VERSION "created by canmatrix"

NS_ :

BS_:

BU_: ABS BCU ESL PKE VIU BMS DTU OBC

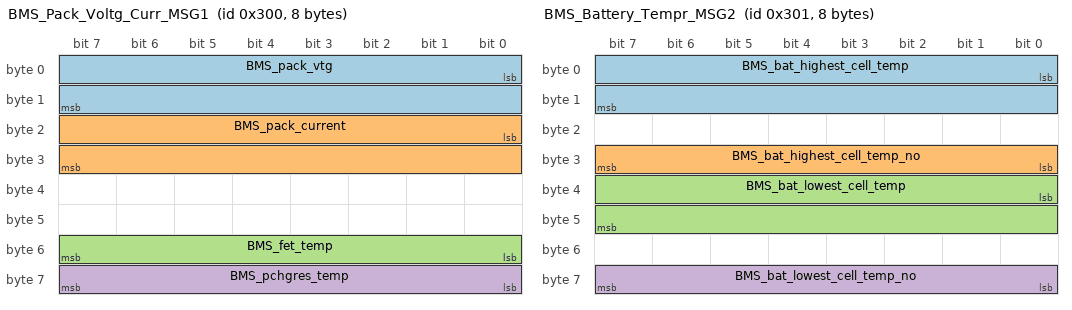
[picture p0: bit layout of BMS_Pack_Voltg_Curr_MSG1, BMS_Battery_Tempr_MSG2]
BO_ 768 BMS_Pack_Voltg_Curr_MSG1: 8 BMS
 SG_ BMS_pack_vtg : 0|16@1+ (0.01,0) [0|65535] "V"  DTU,OBC,VIU
 SG_ BMS_pack_current : 16|16@1- (0.01,0) [-32768|32767] "A"  DTU,OBC,VIU
 SG_ BMS_fet_temp : 48|8@1- (1,0) [-128|127] "degC"  DTU,OBC,VIU
 SG_ BMS_pchgres_temp : 56|8@1- (1,0) [-128|127] "degC"  DTU,OBC,VIU

BO_ 769 BMS_Battery_Tempr_MSG2: 8 BMS
 SG_ BMS_bat_highest_cell_temp : 0|16@1- (0.01,0) [-32768|32767] "degC"  DTU,VIU
 SG_ BMS_bat_highest_cell_temp_no : 24|8@1+ (1,0) [0|255] ""  DTU,VIU
 SG_ BMS_bat_lowest_cell_temp : 32|16@1- (0.01,0) [-32768|32767] "degC"  DTU,VIU
 SG_ BMS_bat_lowest_cell_temp_no : 56|8@1+ (1,0) [0|255] ""  DTU,VIU

BO_ 770 BMS_Battery_CS_Tempr_MSG3: 8 BMS
 SG_ BMS_delta_cell_temp : 0|16@1- (0.01,0) [-32768|32767] "degC"  DTU,VIU
 SG_ BMS_cstemp : 16|16@1- (0.01,0) [-32768|32767] "degC"  DTU,VIU
 SG_ BMS_delta_cell_vtg : 32|16@1- (0.001,0) [-32768|32767] "V"  DTU,VIU

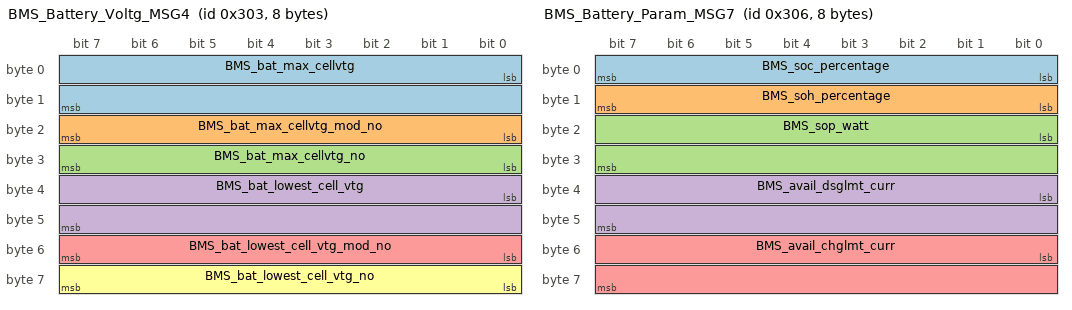
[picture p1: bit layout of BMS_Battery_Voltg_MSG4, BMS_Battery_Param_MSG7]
BO_ 771 BMS_Battery_Voltg_MSG4: 8 BMS
 SG_ BMS_bat_max_cellvtg : 0|16@1+ (0.001,0) [0|65535] "V"  DTU,OBC,VIU
 SG_ BMS_bat_max_cellvtg_mod_no : 16|8@1+ (1,0) [0|255] ""  DTU,OBC,VIU
 SG_ BMS_bat_max_cellvtg_no : 24|8@1+ (1,0) [0|255] ""  DTU,OBC,VIU
 SG_ BMS_bat_lowest_cell_vtg : 32|16@1+ (0.001,0) [0|65535] "V"  DTU,OBC,VIU
 SG_ BMS_bat_lowest_cell_vtg_mod_no : 48|8@1+ (1,0) [0|255] ""  DTU,OBC,VIU
 SG_ BMS_bat_lowest_cell_vtg_no : 56|8@1+ (1,0) [0|255] ""  DTU,OBC,VIU

BO_ 772 BMS_Battery_Param_MSG5: 8 BMS
 SG_ BMS_bat_full_capacity : 0|16@1+ (0.01,0) [0|65535] "Ah"  DTU,OBC,VIU
 SG_ BMS_bat_remaining_capacity : 32|16@1+ (0.001,0) [0|65535] "Ah"  DTU,OBC,VIU
 SG_ BMS_bat_no_of_cycle : 48|16@1+ (1,0) [0|65535] ""  DTU,OBC,VIU

BO_ 773 BMS_Battery_State_MSG6: 8 BMS
 SG_ BMS_state : 0|6@1+ (1,0) [0|63] "State"  BCU,DTU,OBC,VIU
 SG_ BMS_scd_fb_status : 6|1@1+ (1,0) [0|1] "Status"  BCU,DTU,OBC,VIU
 SG_ BMS_charger_detect_status : 7|1@1+ (1,0) [0|1] "Status"  BCU,DTU,OBC,VIU
 SG_ BMS_fet_state : 8|3@1+ (1,0) [0|7] "State"  BCU,DTU,OBC,VIU
 SG_ BMS_CS_state : 11|2@1+ (1,0) [0|3] "State"  BCU,DTU,OBC,VIU
 SG_ BMS_chg_mcu_status : 13|1@1+ (1,0) [0|1] "Status"  BCU,DTU,OBC,VIU
 SG_ BMS_dchg_mcu_status : 14|1@1+ (1,0) [0|1] "Status"  BCU,DTU,OBC,VIU
 SG_ BMS_dchg_fb_status : 15|1@1+ (1,0) [0|1] "Status"  BCU,DTU,OBC,VIU
 SG_ BMS_calib_start_status : 16|1@1+ (1,0) [0|1] "Status"  BCU,DTU,OBC,VIU
 SG_ BMS_sop_derating_flag : 17|1@1+ (1,0) [0|1] "Status"  BCU,DTU,OBC,VIU
 SG_ BMS_charger_plugged_status : 18|1@1+ (1,0) [0|1] "Status"  BCU,DTU,OBC,VIU
 SG_ BMS_cstemp_warn_status : 19|1@1+ (1,0) [0|1] "Status"  BCU,DTU,OBC,VIU
 SG_ BMS_regen_disable_flag : 20|1@1+ (1,0) [0|1] "Status"  BCU,DTU,OBC,VIU
 SG_ BMS_diagchk_BattStatus : 24|2@1+ (1,0) [0|3] "Status"  BCU,DTU,OBC,VIU
 SG_ BMS_diagchk_BattTemp : 26|2@1+ (1,0) [0|3] "Status"  BCU,DTU,OBC,VIU
 SG_ BMS_diagchk_BattVtg : 28|2@1+ (1,0) [0|3] "Status"  BCU,DTU,OBC,VIU
 SG_ BMS_diagchk_CoolantTemp : 30|2@1+ (1,0) [0|3] "Status"  BCU,DTU,OBC,VIU
 SG_ BMS_cantx_status : 32|1@1+ (1,0) [0|1] "Status"  BCU,DTU,OBC,VIU
 SG_ BMS_bcucanrx_status : 33|1@1+ (1,0) [0|1] "Status"  BCU,DTU,OBC,VIU
 SG_ BMS_dtucanrx_status : 34|1@1+ (1,0) [0|1] "Status"  BCU,DTU,OBC,VIU
 SG_ BMS_obccanrx_status : 35|1@1+ (1,0) [0|1] "Status"  BCU,DTU,OBC,VIU
 SG_ BMS_viucanrx_status : 36|1@1+ (1,0) [0|1] "Status"  BCU,DTU,OBC,VIU
 SG_ BMS_abscanrx_status : 37|1@1+ (1,0) [0|1] "Status"  BCU,DTU,OBC,VIU
 SG_ BMS_pkecanrx_status : 38|1@1+ (1,0) [0|1] "Status"  BCU,DTU,OBC,VIU
 SG_ BMS_esclcanrx_status : 39|1@1+ (1,0) [0|1] "Status"  BCU,DTU,OBC,VIU
 SG_ BMS_can_state : 40|2@1+ (1,0) [0|3] "x"  BCU,DTU,OBC,VIU
 SG_ BMS_chgr_full_status : 42|1@1+ (1,0) [0|1] "Status"  BCU,DTU,OBC,VIU
 SG_ BMS_fchgr_pres_status : 43|1@1+ (1,0) [0|1] "Status"  BCU,DTU,OBC,VIU
 SG_ BMS_chgr_fault_status : 44|1@1+ (1,0) [0|1] "Status"  BCU,DTU,OBC,VIU
 SG_ BMS_eol_mode : 45|1@1+ (1,0) [0|1] "Status"  BCU,DTU,OBC,VIU

BO_ 774 BMS_Battery_Param_MSG7: 8 BMS
 SG_ BMS_soc_percentage : 0|8@1+ (1,0) [0|255] "%"  DTU,OBC,VIU
 SG_ BMS_soh_percentage : 8|8@1+ (1,0) [0|255] "%"  DTU,OBC,VIU
 SG_ BMS_sop_watt : 16|16@1+ (1,0) [0|65535] "W"  DTU,OBC,VIU
 SG_ BMS_avail_dsglmt_curr : 32|16@1+ (0.01,0) [0|65535] "A"  DTU,OBC,VIU
 SG_ BMS_avail_chglmt_curr : 48|16@1+ (0.01,0) [0|65535] "A"  DTU,OBC,VIU

BO_ 512 BMS_AFE_MCU_Faults_MSG9: 8 BMS
 SG_ BMS_afe_cov_fault : 0|1@1+ (1,0) [0|1] "Status"  BCU,DTU,OBC,VIU
 SG_ BMS_afe_cuv_fault : 1|1@1+ (1,0) [0|1] "Status"  BCU,DTU,OBC,VIU
 SG_ BMS_afe_cot_chg_fault : 2|1@1+ (1,0) [0|1] "Status"  BCU,DTU,OBC,VIU
 SG_ BMS_afe_cot_dchg_fault : 3|1@1+ (1,0) [0|1] "Status"  BCU,DTU,OBC,VIU
 SG_ BMS_afe_cut_chg_fault : 4|1@1+ (1,0) [0|1] "Status"  BCU,DTU,OBC,VIU
 SG_ BMS_afe_cut_dchg_fault : 5|1@1+ (1,0) [0|1] "Status"  BCU,DTU,OBC,VIU
 SG_ BMS_afe_oc_chg_fault : 6|1@1+ (1,0) [0|1] "Status"  BCU,DTU,OBC,VIU
 SG_ BMS_afe_oc_dchg_fault : 7|1@1+ (1,0) [0|1] "Status"  BCU,DTU,OBC,VIU
 SG_ BMS_afe_sc_detetction_fault : 8|1@1+ (1,0) [0|1] "Status"  BCU,DTU,OBC,VIU
 SG_ BMS_afe_overload_detect_fault : 9|1@1+ (1,0) [0|1] "Status"  BCU,DTU,OBC,VIU
 SG_ BMS_afe_fet_off_fault : 10|1@1+ (1,0) [0|1] "Status"  BCU,DTU,OBC,VIU
 SG_ BMS_afe_oc_fault : 11|1@1+ (1,0) [0|1] "Status"  BCU,DTU,OBC,VIU
 SG_ BMS_afe_otf_fault : 12|1@1+ (1,0) [0|1] "Status"  BCU,DTU,OBC,VIU
 SG_ BMS_chgfetoff_fault : 13|1@1+ (1,0) [0|1] "Status"  BCU,DTU,OBC,VIU
 SG_ BMS_dsgfetoff_fault : 14|1@1+ (1,0) [0|1] ""  BCU,DTU,OBC,VIU
 SG_ BMS_cov_fault : 16|1@1+ (1,0) [0|1] "Status"  BCU,DTU,OBC,VIU
 SG_ BMS_cuv_fault : 17|1@1+ (1,0) [0|1] "Status"  BCU,DTU,OBC,VIU
 SG_ BMS_ddsg_fault : 18|1@1+ (1,0) [0|1] "Status"  BCU,DTU,OBC,VIU
 SG_ BMS_del_cv_fault : 19|1@1+ (1,0) [0|1] "Status"  BCU,DTU,OBC,VIU
 SG_ BMS_pchg_tout_fault : 20|1@1+ (1,0) [0|1] "Status"  BCU,DTU,OBC,VIU
 SG_ BMS_del_ct_fault : 21|1@1+ (1,0) [0|1] "Status"  BCU,DTU,OBC,VIU
 SG_ BMS_hostl_i2c_fault : 22|1@1+ (1,0) [0|1] "Status"  BCU,DTU,OBC,VIU
 SG_ BMS_hostu_i2c_fault : 23|1@1+ (1,0) [0|1] "Status"  BCU,DTU,OBC,VIU
 SG_ BMS_cot_chg_fault : 24|1@1+ (1,0) [0|1] "Status"  BCU,DTU,OBC,VIU
 SG_ BMS_cot_dsg_fault : 25|1@1+ (1,0) [0|1] "Status"  BCU,DTU,OBC,VIU
 SG_ BMS_cut_chg_fault : 26|1@1+ (1,0) [0|1] "Status"  BCU,DTU,OBC,VIU
 SG_ BMS_cut_dsg_fault : 27|1@1+ (1,0) [0|1] "Status"  BCU,DTU,OBC,VIU
 SG_ BMS_fot_fault : 28|1@1+ (1,0) [0|1] "Status"  BCU,DTU,OBC,VIU
 SG_ BMS_csot_fault : 29|1@1+ (1,0) [0|1] "Status"  BCU,DTU,OBC,VIU
 SG_ BMS_afedieot_fault : 30|1@1+ (1,0) [0|1] "Status"  BCU,DTU,OBC,VIU
 SG_ BMS_imd_fault : 31|1@1+ (1,0) [0|1] "Status"  BCU,DTU,OBC,VIU
 SG_ BMS_cvow_fault : 33|1@1+ (1,0) [0|1] "Status"  BCU,DTU,OBC,VIU
 SG_ BMS_ctow_fault : 34|1@1+ (1,0) [0|1] "Status"  BCU,DTU,OBC,VIU
 SG_ BMS_nctow_fault : 35|1@1+ (1,0) [0|1] "Status"  BCU,DTU,OBC,VIU
 SG_ BMS_cs_ic_fail_fault : 36|1@1+ (1,0) [0|1] "Status"  BCU,DTU,OBC,VIU
 SG_ BMS_imd_ic_fail_fault : 37|1@1+ (1,0) [0|1] "Status"  BCU,DTU,OBC,VIU
 SG_ BMS_ftow_fault : 38|1@1+ (1,0) [0|1] "Status"  BCU,DTU,OBC,VIU
 SG_ BMS_cstow_fault : 39|1@1+ (1,0) [0|1] "Status"  BCU,DTU,OBC,VIU
 SG_ BMS_aps_scd_fault : 40|1@1+ (1,0) [0|1] "Status"  BCU,DTU,OBC,VIU
 SG_ BMS_aps_ot_fault : 41|1@1+ (1,0) [0|1] "Status"  BCU,DTU,OBC,VIU
 SG_ BMS_aps_ov_fault : 42|1@1+ (1,0) [0|1] "Status"  BCU,DTU,OBC,VIU
 SG_ BMS_aps_oc_fault : 43|1@1+ (1,0) [0|1] "Status"  BCU,DTU,OBC,VIU
 SG_ BMS_fetchg_short_fault : 44|1@1+ (1,0) [0|1] "Status"  BCU,DTU,OBC,VIU
 SG_ BMS_fetdsg_short_fault : 45|1@1+ (1,0) [0|1] "Status"  BCU,DTU,OBC,VIU
 SG_ BMS_pchg_pk_fault : 46|1@1+ (1,0) [0|1] "Status"  BCU,DTU,OBC,VIU
 SG_ BMS_crit_rel_fault : 47|1@1+ (1,0) [0|1] "Status"  BCU,DTU,OBC,VIU
 SG_ BMS_pchg_rot_fault : 48|1@1+ (1,0) [0|1] "Status"  BCU,DTU,OBC,VIU
 SG_ BMS_pchg_rtow_fault : 49|1@1+ (1,0) [0|1] "Status"  BCU,DTU,OBC,VIU
 SG_ BMS_chg_hb_fault : 50|1@1+ (1,0) [0|1] "Status"  BCU,DTU,OBC,VIU
 SG_ BMS_hvil_fault : 51|1@1+ (1,0) [0|1] "Status"  BCU,DTU,OBC,VIU
 SG_ BMS_dsgoff_rel_fault : 52|1@1+ (1,0) [0|1] "Status"  BCU,DTU,OBC,VIU
 SG_ BMS_hazard_fault : 53|1@1+ (1,0) [0|1] "Status"  BCU,DTU,OBC,VIU
 SG_ BMS_hw_scd_fault : 54|1@1+ (1,0) [0|1] "Status"  BCU,DTU,OBC,VIU
 SG_ BMS_sysfail_fault : 55|1@1+ (1,0) [0|1] "Status"  BCU,DTU,OBC,VIU
 SG_ BMS_other_i2c_fault : 56|1@1+ (1,0) [0|1] "Status"  BCU,DTU,OBC,VIU
 SG_ BMS_aps_oclat_fault : 57|1@1+ (1,0) [0|1] "Status"  BCU,DTU,OBC,VIU
 SG_ BMS_aps_oclat_permfault : 58|1@1+ (1,0) [0|1] "Status"  BCU,DTU,OBC,VIU
 SG_ BMS_ext_opdis_fault : 59|1@1+ (1,0) [0|1] "Status"  BCU,DTU,OBC,VIU
 SG_ BMS_false_chgr_fault : 60|1@1+ (1,0) [0|1] "Status"  BCU,DTU,OBC,VIU
 SG_ BMS_occ1_fault : 61|1@1+ (1,0) [0|1] "Status"  BCU,DTU,OBC,VIU
 SG_ BMS_occ2_fault : 62|1@1+ (1,0) [0|1] "Status"  BCU,DTU,OBC,VIU
 SG_ BMS_occ3_fault : 63|1@1+ (1,0) [0|1] "Status"  BCU,DTU,OBC,VIU

BO_ 513 BMS_Warning_MSG10: 8 BMS
 SG_ BMS_bat_cov_warning : 0|1@1+ (1,0) [0|1] "Status"  BCU,DTU,OBC,VIU
 SG_ BMS_bat_cuv_warning : 1|1@1+ (1,0) [0|1] "Status"  BCU,DTU,OBC,VIU
 SG_ BMS_bat_del_v_warning : 2|1@1+ (1,0) [0|1] "Status"  BCU,DTU,OBC,VIU
 SG_ BMS_bat_cot_warning : 3|1@1+ (1,0) [0|1] "Status"  BCU,DTU,OBC,VIU
 SG_ BMS_bat_cut_warning : 4|1@1+ (1,0) [0|1] "Status"  BCU,DTU,OBC,VIU
 SG_ BMS_bat_del_ct_warning : 5|1@1+ (1,0) [0|1] "Status"  BCU,DTU,OBC,VIU
 SG_ BMS_bat_fot_warning : 6|1@1+ (1,0) [0|1] "Status"  BCU,DTU,OBC,VIU
 SG_ BMS_bat_csot_warning : 7|1@1+ (1,0) [0|1] "Status"  BCU,DTU,OBC,VIU
 SG_ BMS_bat_afedieot_warning : 8|1@1+ (1,0) [0|1] "Status"  BCU,DTU,OBC,VIU
 SG_ BMS_bat_occ_warning : 9|1@1+ (1,0) [0|1] "Status"  BCU,DTU,OBC,VIU
 SG_ BMS_bat_ocd_warning : 10|1@1+ (1,0) [0|1] "Status"  BCU,DTU,OBC,VIU
 SG_ BMS_bat_pusoc_warning : 11|1@1+ (1,0) [0|1] "Status"  BCU,DTU,OBC,VIU
 SG_ BMS_hvil_warning : 12|1@1+ (1,0) [0|1] "Status"  BCU,DTU,OBC,VIU
 SG_ BMS_bat_imd_warning : 13|1@1+ (1,0) [0|1] "Status"  BCU,DTU,OBC,VIU
 SG_ BMS_batcrit_lvl1_warning : 14|1@1+ (1,0) [0|1] "Status"  BCU,DTU,OBC,VIU
 SG_ BMS_batcrit_lvl2_warning : 15|1@1+ (1,0) [0|1] "Status"  BCU,DTU,OBC,VIU
 SG_ BMS_hostl_i2c_warning : 16|1@1+ (1,0) [0|1] "Status"  BCU,DTU,OBC,VIU
 SG_ BMS_hostu_i2c_warning : 17|1@1+ (1,0) [0|1] "Status"  BCU,DTU,OBC,VIU
 SG_ BMS_pump_oload_warning : 18|1@1+ (1,0) [0|1] "Status"  BCU,DTU,OBC,VIU
 SG_ BMS_dpdsg_warning : 19|1@1+ (1,0) [0|1] "Status"  BCU,DTU,OBC,VIU
 SG_ BMS_cotc_warning : 20|1@1+ (1,0) [0|1] "Status"  BCU,DTU,OBC,VIU
 SG_ BMS_cutc_warning : 21|1@1+ (1,0) [0|1] "Status"  BCU,DTU,OBC,VIU

BO_ 514 BMS_Iso_Resist_MSG11: 8 BMS
 SG_ BMS_iso_res_pcgnd : 0|32@1- (0.001,0) [-2147483648|2147483647] "Ohm"  DTU,OBC,VIU
 SG_ BMS_iso_res_ncgnd : 32|32@1- (0.001,0) [-2147483648|2147483647] "Ohm"  DTU,OBC,VIU

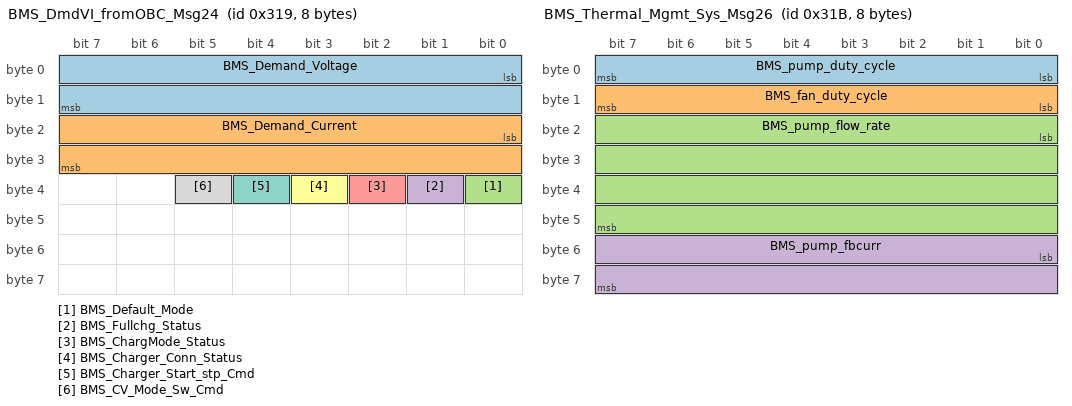
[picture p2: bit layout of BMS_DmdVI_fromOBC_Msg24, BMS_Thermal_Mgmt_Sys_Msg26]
BO_ 793 BMS_DmdVI_fromOBC_Msg24: 8 BMS
 SG_ BMS_Demand_Voltage : 0|16@1+ (0.1,0) [0|65535] "V"  OBC,VIU
 SG_ BMS_Demand_Current : 16|16@1- (0.01,0) [-32768|32767] "A"  OBC,VIU
 SG_ BMS_Default_Mode : 32|1@1+ (1,0) [0|1] ""  OBC,VIU
 SG_ BMS_Fullchg_Status : 33|1@1+ (1,0) [0|1] ""  OBC,VIU
 SG_ BMS_ChargMode_Status : 34|1@1+ (1,0) [0|1] "Status"  OBC,VIU
 SG_ BMS_Charger_Conn_Status : 35|1@1+ (1,0) [0|1] "Status"  OBC,VIU
 SG_ BMS_Charger_Start_stp_Cmd : 36|1@1+ (1,0) [0|1] "Cmd"  OBC,VIU
 SG_ BMS_CV_Mode_Sw_Cmd : 37|1@1+ (1,0) [0|1] "Mode"  OBC,VIU

BO_ 794 BMS_Heart_beat_Msg25: 8 BMS
 SG_ BMS_code_m25 : 0|8@1+ (1,0) [0|255] "ECUs"  BCU,DTU,OBC,VIU
 SG_ BMS_Rolling_Counter : 8|8@1+ (1,0) [0|255] ""  BCU,DTU,OBC,VIU

BO_ 795 BMS_Thermal_Mgmt_Sys_Msg26: 8 BMS
 SG_ BMS_pump_duty_cycle : 0|8@1+ (1,0) [0|255] "count"  BCU,DTU,OBC,VIU
 SG_ BMS_fan_duty_cycle : 8|8@1+ (1,0) [0|255] "%"  BCU,DTU,OBC,VIU
 SG_ BMS_pump_flow_rate : 16|32@1+ (1,0) [0|4294967295] "lpm"  BCU,DTU,OBC,VIU
 SG_ BMS_pump_fbcurr : 48|16@1- (0.001,0) [-32768|32767] "A"  BCU,DTU,OBC,VIU

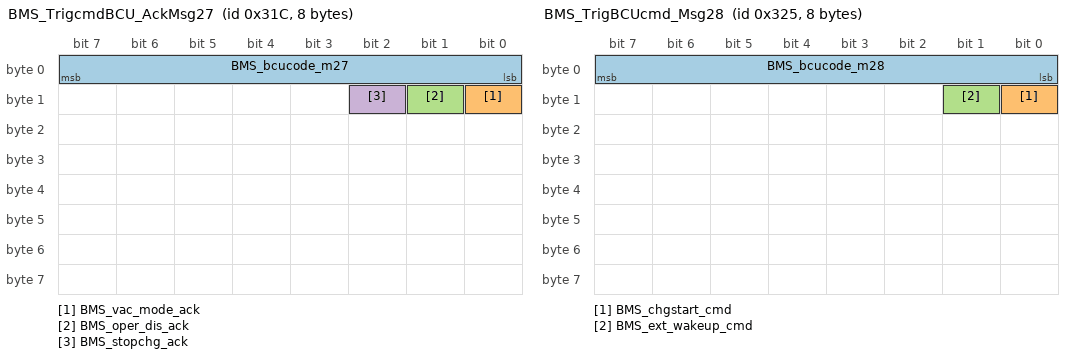
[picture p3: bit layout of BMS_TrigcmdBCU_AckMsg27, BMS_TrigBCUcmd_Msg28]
BO_ 796 BMS_TrigcmdBCU_AckMsg27: 8 BMS
 SG_ BMS_bcucode_m27 : 0|8@1+ (1,0) [0|255] ""  BCU,DTU,OBC,VIU
 SG_ BMS_vac_mode_ack : 8|1@1+ (1,0) [0|1] ""  BCU,DTU,OBC,VIU
 SG_ BMS_oper_dis_ack : 9|1@1+ (1,0) [0|1] ""  BCU,DTU,OBC,VIU
 SG_ BMS_stopchg_ack : 10|1@1+ (1,0) [0|1] ""  BCU,DTU,OBC,VIU

BO_ 805 BMS_TrigBCUcmd_Msg28: 8 BMS
 SG_ BMS_bcucode_m28 : 0|8@1+ (1,0) [0|255] ""  BCU,DTU,OBC,VIU
 SG_ BMS_chgstart_cmd : 8|1@1+ (1,0) [0|1] ""  BCU,DTU,OBC,VIU
 SG_ BMS_ext_wakeup_cmd : 9|1@1+ (1,0) [0|1] ""  BCU,DTU,OBC,VIU

BO_ 2028 BMS_Phy_RespMsg29: 8 BMS
 SG_ BMS_uds_frame : 0|64@1+ (1,0) [0|1.84467440737096E+019] ""  VIU

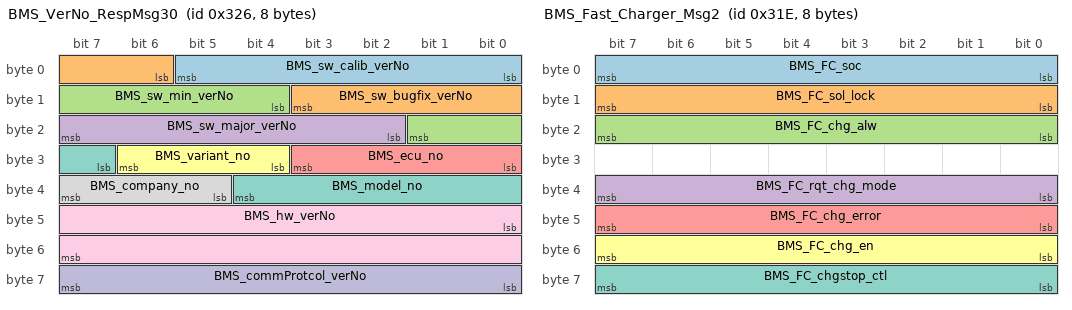
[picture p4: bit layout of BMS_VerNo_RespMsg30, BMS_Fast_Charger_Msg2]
BO_ 806 BMS_VerNo_RespMsg30: 8 BMS
 SG_ BMS_sw_calib_verNo : 0|6@1+ (1,0) [0|63] ""  VIU
 SG_ BMS_sw_bugfix_verNo : 6|6@1+ (1,0) [0|63] ""  VIU
 SG_ BMS_sw_min_verNo : 12|6@1+ (1,0) [0|63] ""  VIU
 SG_ BMS_sw_major_verNo : 18|6@1+ (1,0) [0|63] ""  VIU
 SG_ BMS_ecu_no : 24|4@1+ (1,0) [0|15] ""  VIU
 SG_ BMS_variant_no : 28|3@1+ (1,0) [0|7] ""  VIU
 SG_ BMS_model_no : 31|6@1+ (1,0) [0|63] ""  VIU
 SG_ BMS_company_no : 37|3@1+ (1,0) [0|7] ""  VIU
 SG_ BMS_hw_verNo : 40|16@1+ (1,0) [0|65535] ""  VIU
 SG_ BMS_commProtcol_verNo : 56|8@1+ (1,0) [0|255] ""  VIU

BO_ 807 BMS_VerName_Resp1_Msg31: 8 BMS
 SG_ BMS_extvname1 : 0|64@1+ (1,0) [0|1.84467440737096E+019] ""  VIU

BO_ 808 BMS_VerName_Resp2_Msg32: 8 BMS
 SG_ BMS_extvname2 : 0|64@1+ (1,0) [0|1.84467440737096E+019] ""  VIU

BO_ 797 BMS_Fast_Charger_Msg1: 8 BMS
 SG_ BMS_FC_dmd_voltage : 0|16@1+ (0.01,0) [0|65535] "V "  BCU
 SG_ BMS_FC_dmd_current : 16|16@1- (0.01,0) [-32768|32767] "A "  BCU
 SG_ BMS_FC_start_cmd : 32|8@1+ (1,0) [0|255] ""  BCU

BO_ 798 BMS_Fast_Charger_Msg2: 8 BMS
 SG_ BMS_FC_soc : 0|8@1+ (1,0) [0|255] ""  BCU
 SG_ BMS_FC_sol_lock : 8|8@1+ (1,0) [0|255] ""  BCU
 SG_ BMS_FC_chg_alw : 16|8@1+ (1,0) [0|255] ""  BCU
 SG_ BMS_FC_rqt_chg_mode : 32|8@1+ (1,0) [0|255] ""  BCU
 SG_ BMS_FC_chg_error : 40|8@1+ (1,0) [0|255] ""  BCU
 SG_ BMS_FC_chg_en : 48|8@1+ (1,0) [0|255] ""  BCU
 SG_ BMS_FC_chgstop_ctl : 56|8@1+ (1,0) [0|255] ""  BCU

BO_ 848 BCU_IO_sts_MSG1: 8 BCU
 SG_ BCU_dpad_left_swip_lgpress_sts : 0|1@1+ (1,0) [0|1] "x"  BMS,DTU,OBC,VIU
 SG_ BCU_horn_swip_sts : 1|1@1+ (1,0) [0|1] "x"  BMS,DTU,OBC,VIU
 SG_ BCU_side_stand_sts : 2|1@1+ (1,0) [0|1] "x"  BMS,DTU,OBC,VIU
 SG_ BCU_pwr_swled_sts : 3|1@1+ (1,0) [0|1] "x"  BMS,DTU,OBC,VIU
 SG_ BCU_pwrbtn_dpress_sts : 4|1@1+ (1,0) [0|1] "x"  BMS,DTU,OBC,VIU
 SG_ BCU_usb_enable_sts : 5|1@1+ (1,0) [0|1] "x"  BMS,DTU,OBC,VIU
 SG_ BCU_drl_pwr_sts : 6|1@1+ (1,0) [0|1] "x"  BMS,DTU,OBC,VIU
 SG_ BCU_highbeam_pwr_sts : 7|1@1+ (1,0) [0|1] "x"  BMS,DTU,OBC,VIU
 SG_ BCU_chgr_unloc_pwr_sts : 8|1@1+ (1,0) [0|1] "x"  BMS,DTU,OBC,VIU
 SG_ BCU_dpad_centre_swip_press : 9|1@1+ (1,0) [0|1] "x"  BMS,DTU,OBC,VIU
 SG_ BCU_Dimmer_High_swip_sts : 10|1@1+ (1,0) [0|1] "x"  BMS,DTU,OBC,VIU
 SG_ BCU_pwrbtn_long_press_sts : 11|1@1+ (1,0) [0|1] "x"  BMS,DTU,OBC,VIU
 SG_ BCU_Pass_Light_swip_sts : 12|1@1+ (1,0) [0|1] "x"  BMS,DTU,OBC,VIU
 SG_ BCU_Right_Signal_swip_sts : 13|1@1+ (1,0) [0|1] "x"  BMS,DTU,OBC,VIU
 SG_ BCU_Left_Signal_swip_sts : 14|1@1+ (1,0) [0|1] "x"  BMS,DTU,OBC,VIU
 SG_ BCU_dualsig_sw_sts : 15|1@1+ (1,0) [0|1] "x"  BMS,DTU,OBC,VIU
 SG_ BCU_dpad_up_swip_lgpress_sts : 16|1@1+ (1,0) [0|1] "x"  BMS,DTU,OBC,VIU
 SG_ BCU_dpad_up_swip_press_sts : 17|1@1+ (1,0) [0|1] "x"  BMS,DTU,OBC,VIU
 SG_ BCU_dpad_down_swip_press_sts : 18|1@1+ (1,0) [0|1] "x"  BMS,DTU,OBC,VIU
 SG_ BCU_dpad_down_swip_lgpress_sts : 19|1@1+ (1,0) [0|1] "x"  BMS,DTU,OBC,VIU
 SG_ BCU_dpad_left_swip_sts : 20|1@1+ (1,0) [0|1] "x"  BMS,DTU,OBC,VIU
 SG_ BCU_dpad_right_swip_sts : 21|1@1+ (1,0) [0|1] "x"  BMS,DTU,OBC,VIU
 SG_ BCU_chgr_solend_lock_sts : 22|1@1+ (1,0) [0|1] "x"  BMS,DTU,OBC,VIU
 SG_ BCU_keyfob_missing_sts : 23|1@1+ (1,0) [0|1] "x"  BMS,DTU,OBC,VIU
 SG_ BCU_chg_sub_modes : 24|2@1+ (1,0) [0|3] "x"  BMS,DTU,OBC,VIU
 SG_ BCU_vic_pwrout_sts : 26|1@1+ (1,0) [0|1] "x"  BMS,DTU,OBC,VIU
 SG_ BCU_dimmer_lo_pwr_sts : 27|1@1+ (1,0) [0|1] "x"  BMS,DTU,OBC,VIU
 SG_ BCU_horn_pwr_sts : 28|1@1+ (1,0) [0|1] "x"  BMS,DTU,OBC,VIU
 SG_ BCU_tlamp_pwr_sts : 29|1@1+ (1,0) [0|1] "x"  BMS,DTU,OBC,VIU
 SG_ BCU_bootlamp_pwr_sts : 30|1@1+ (1,0) [0|1] "x"  BMS,DTU,OBC,VIU
 SG_ BCU_vic_reset_pin_sts : 31|1@1+ (1,0) [0|1] "x"  BMS,DTU,OBC,VIU
 SG_ BCU_veh_dbc_verno : 32|8@1+ (1,0) [0|255] "x"  BMS,DTU,OBC,VIU
 SG_ BCU_buzzer_pwr_sts : 40|1@1+ (1,0) [0|1] "x"  BMS,DTU,OBC,VIU
 SG_ BCU_tsl_pwr_sts : 41|1@1+ (1,0) [0|1] "x"  BMS,DTU,OBC,VIU
 SG_ BCU_dualsig_sw_lngpres_sts : 42|1@1+ (1,0) [0|1] "x"  BMS,DTU,OBC,VIU
 SG_ BCU_storage_loc_sw_sts : 43|1@1+ (1,0) [0|1] "x"  BMS,DTU,OBC,VIU
 SG_ BCU_dpadcen_sw_lngpress : 44|1@1+ (1,0) [0|1] "x"  BMS,DTU,OBC,VIU
 SG_ BCU_left_sig_blink_pwr_sts : 45|1@1+ (1,0) [0|1] "x"  BMS,DTU,OBC,VIU
 SG_ BCU_right_sig_blink_pwr_sts : 46|1@1+ (1,0) [0|1] "x"  BMS,DTU,OBC,VIU
 SG_ BCU_chgr_loc_pwr_sts : 47|1@1+ (1,0) [0|1] "x"  BMS,DTU,OBC,VIU
 SG_ BCU_gear_position : 48|3@1+ (1,0) [0|7] "x"  BMS,DTU,OBC,VIU
 SG_ BCU_vic_hwrst_sts : 51|1@1+ (1,0) [0|1] "x"  BMS,DTU,OBC,VIU
 SG_ BCU_fan_pwr_sts : 52|1@1+ (1,0) [0|1] "x"  BMS,DTU,OBC,VIU
 SG_ BCU_stoplp_pwr_sts : 53|1@1+ (1,0) [0|1] "x"  BMS,DTU,OBC,VIU
 SG_ BCU_pwrbtn_spress_sts : 54|1@1+ (1,0) [0|1] "x"  BMS,DTU,OBC,VIU
 SG_ BCU_vehfault_sts : 55|1@1+ (1,0) [0|1] "x"  BMS,DTU,OBC,VIU
 SG_ BCU_vehicle_mode : 56|4@1+ (1,0) [0|15] ""  BMS,DTU,OBC,VIU
 SG_ BCU_ride_sub_modes : 60|2@1+ (1,0) [0|3] "Mode"  BMS,DTU,OBC,VIU
 SG_ BCU_parkassist_sub_modes : 62|1@1+ (1,0) [0|1] ""  BMS,DTU,OBC,VIU
 SG_ BCU_dpad_centre_dpress : 63|1@1+ (1,0) [0|1] ""  BMS,DTU,OBC,VIU

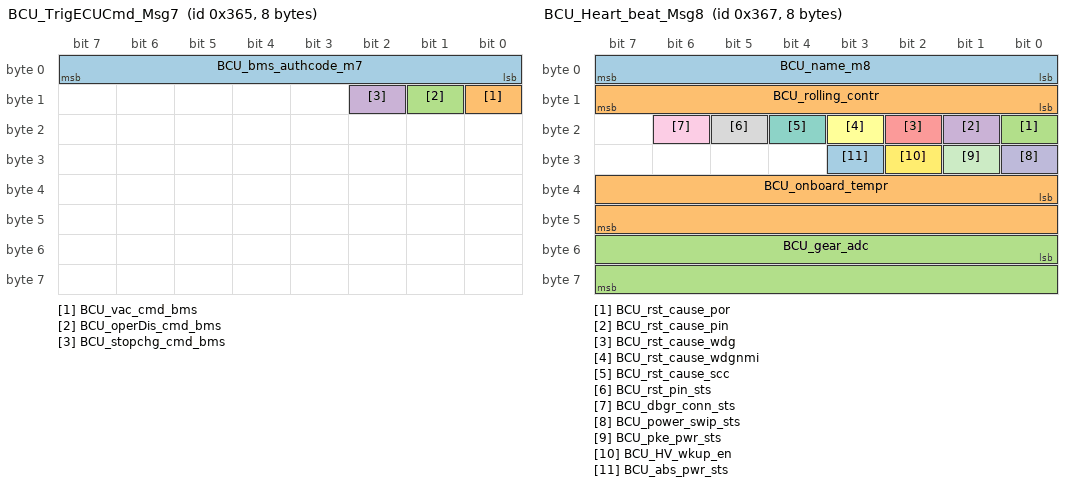
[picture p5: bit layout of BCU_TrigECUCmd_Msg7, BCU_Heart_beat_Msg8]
BO_ 869 BCU_TrigECUCmd_Msg7: 8 BCU
 SG_ BCU_bms_authcode_m7 : 0|8@1+ (1,0) [0|255] ""  BMS
 SG_ BCU_vac_cmd_bms : 8|1@1+ (1,0) [0|1] ""  BMS
 SG_ BCU_operDis_cmd_bms : 9|1@1+ (1,0) [0|1] ""  BMS
 SG_ BCU_stopchg_cmd_bms : 10|1@1+ (1,0) [0|1] ""  BMS

BO_ 871 BCU_Heart_beat_Msg8: 8 BCU
 SG_ BCU_name_m8 : 0|8@1+ (1,0) [0|255] ""  BMS,DTU,OBC,VIU
 SG_ BCU_rolling_contr : 8|8@1+ (1,0) [0|255] ""  BMS,DTU,OBC,VIU
 SG_ BCU_rst_cause_por : 16|1@1+ (1,0) [0|1] "x"  BMS,DTU,OBC,VIU
 SG_ BCU_rst_cause_pin : 17|1@1+ (1,0) [0|1] "x"  BMS,DTU,OBC,VIU
 SG_ BCU_rst_cause_wdg : 18|1@1+ (1,0) [0|1] "x"  BMS,DTU,OBC,VIU
 SG_ BCU_rst_cause_wdgnmi : 19|1@1+ (1,0) [0|1] "x"  BMS,DTU,OBC,VIU
 SG_ BCU_rst_cause_scc : 20|1@1+ (1,0) [0|1] "x"  BMS,DTU,OBC,VIU
 SG_ BCU_rst_pin_sts : 21|1@1+ (1,0) [0|1] "x"  BMS,DTU,OBC,VIU
 SG_ BCU_dbgr_conn_sts : 22|1@1+ (1,0) [0|1] "x"  BMS,DTU,OBC,VIU
 SG_ BCU_power_swip_sts : 24|1@1+ (1,0) [0|1] "x"  BMS,DTU,OBC,VIU
 SG_ BCU_pke_pwr_sts : 25|1@1+ (1,0) [0|1] "x"  BMS,DTU,OBC,VIU
 SG_ BCU_HV_wkup_en : 26|1@1+ (1,0) [0|1] "x"  BMS,DTU,OBC,VIU
 SG_ BCU_abs_pwr_sts : 27|1@1+ (1,0) [0|1] "x"  BMS,DTU,OBC,VIU
 SG_ BCU_onboard_tempr : 32|16@1- (1,0) [-32768|32767] "degC"  BMS,DTU,OBC,VIU
 SG_ BCU_gear_adc : 48|16@1+ (1,0) [0|65535] "x"  BMS,DTU,OBC,VIU

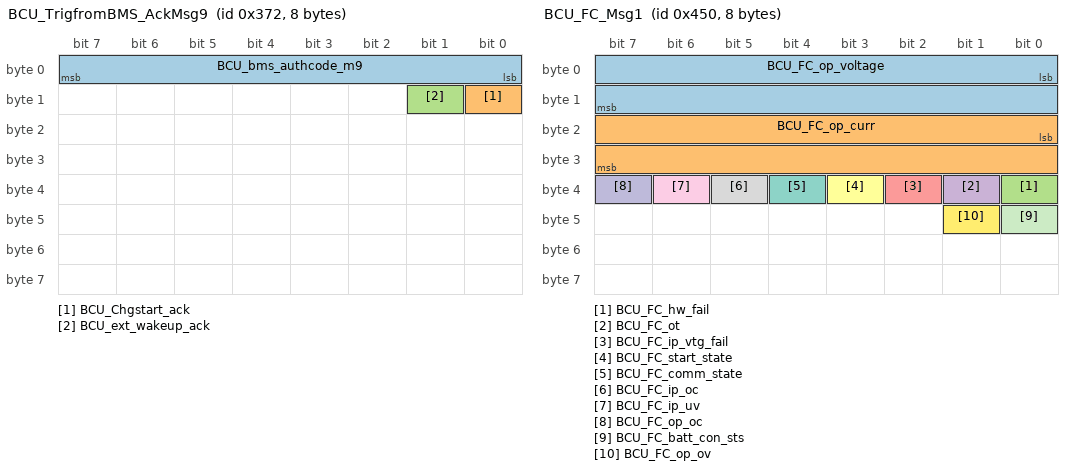
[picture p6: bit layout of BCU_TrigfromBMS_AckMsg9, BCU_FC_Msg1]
BO_ 882 BCU_TrigfromBMS_AckMsg9: 8 BCU
 SG_ BCU_bms_authcode_m9 : 0|8@1+ (1,0) [0|255] ""  BMS
 SG_ BCU_Chgstart_ack : 8|1@1+ (1,0) [0|1] ""  BMS
 SG_ BCU_ext_wakeup_ack : 9|1@1+ (1,0) [0|1] ""  BMS

BO_ 1104 BCU_FC_Msg1: 8 BCU
 SG_ BCU_FC_op_voltage : 0|16@1+ (0.1,0) [0|65535] "V "  BMS
 SG_ BCU_FC_op_curr : 16|16@1- (0.1,0) [-32768|32767] "A"  BMS
 SG_ BCU_FC_hw_fail : 32|1@1+ (1,0) [0|1] ""  BMS
 SG_ BCU_FC_ot : 33|1@1+ (1,0) [0|1] ""  BMS
 SG_ BCU_FC_ip_vtg_fail : 34|1@1+ (1,0) [0|1] ""  BMS
 SG_ BCU_FC_start_state : 35|1@1+ (1,0) [0|1] ""  BMS
 SG_ BCU_FC_comm_state : 36|1@1+ (1,0) [0|1] ""  BMS
 SG_ BCU_FC_ip_oc : 37|1@1+ (1,0) [0|1] ""  BMS
 SG_ BCU_FC_ip_uv : 38|1@1+ (1,0) [0|1] ""  BMS
 SG_ BCU_FC_op_oc : 39|1@1+ (1,0) [0|1] ""  BMS
 SG_ BCU_FC_batt_con_sts : 40|1@1+ (1,0) [0|1] ""  BMS
 SG_ BCU_FC_op_ov : 41|1@1+ (1,0) [0|1] ""  BMS

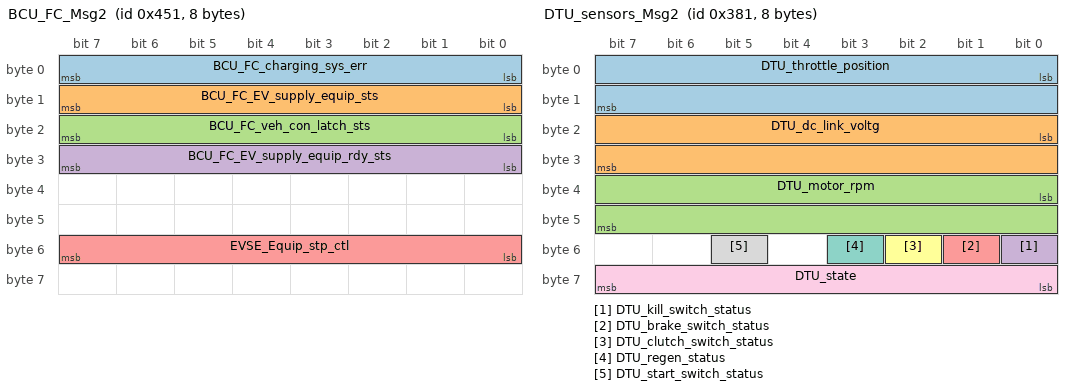
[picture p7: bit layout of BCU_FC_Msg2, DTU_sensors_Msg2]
BO_ 1105 BCU_FC_Msg2: 8 BCU
 SG_ BCU_FC_charging_sys_err : 0|8@1+ (1,0) [0|255] ""  BMS
 SG_ BCU_FC_EV_supply_equip_sts : 8|8@1+ (1,0) [0|255] ""  BMS
 SG_ BCU_FC_veh_con_latch_sts : 16|8@1+ (1,0) [0|255] ""  BMS
 SG_ BCU_FC_EV_supply_equip_rdy_sts : 24|8@1+ (1,0) [0|255] ""  BMS
 SG_ EVSE_Equip_stp_ctl : 48|8@1+ (1,0) [0|255] ""  BMS

BO_ 1282 VIU_VerNo_Msg1: 8 VIU
 SG_ VIU_ecu_name_m1 : 0|8@1+ (1,0) [0|255] ""  BCU,BMS,DTU,OBC

BO_ 1284 VIU_getECUName_Msg2: 8 VIU
 SG_ VIU_ecu_name_m2 : 0|8@1+ (1,0) [0|255] ""  BCU,BMS,DTU,OBC

BO_ 1393 VIU_Event_Msg4: 8 VIU
 SG_ VIU_ride_mode_cmd : 0|2@1+ (1,0) [0|3] ""  BCU,BMS,DTU,OBC
 SG_ VIU_park_assist_cmd : 2|2@1+ (1,0) [0|3] ""  BCU,BMS,DTU,OBC
 SG_ VIU_park_assist_sub_mode_cmd : 4|2@1+ (1,0) [0|3] ""  BCU,BMS,DTU,OBC
 SG_ VIU_usb_en_cmd : 6|2@1+ (1,0) [0|3] ""  BCU,BMS,DTU,OBC
 SG_ VIU_minThreshold_SOC : 8|8@1+ (1,0) [0|255] ""  BCU,BMS,DTU,OBC
 SG_ VIU_Battery_saving_mode_cmd : 16|1@1+ (1,0) [0|1] ""  BCU,BMS,DTU,OBC
 SG_ VIU_park_assist_buzz_cmd : 17|1@1+ (1,0) [0|1] ""  BCU,BMS,DTU,OBC
 SG_ VIU_indicator_buzz_cmd : 18|1@1+ (1,0) [0|1] ""  BCU,BMS,DTU,OBC
 SG_ VIU_follow_me_hlamp_cmd : 19|1@1+ (1,0) [0|1] ""  BCU,BMS,DTU,OBC
 SG_ VIC_remote_lock_unlock_cmd : 20|1@1+ (1,0) [0|1] ""  BCU,BMS,DTU,OBC
 SG_ VIU_auto_ind_off_cmd : 21|1@1+ (1,0) [0|1] ""  BCU,BMS,DTU,OBC
 SG_ VIU_turn_completed_cmd : 22|1@1+ (1,0) [0|1] ""  BCU,BMS,DTU,OBC
 SG_ VIU_sidestd_ignor_cmd : 23|1@1+ (1,0) [0|1] ""  BCU,BMS,DTU,OBC
 SG_ VIU_veh_bootup_lght_cmd : 24|1@1+ (1,0) [0|1] ""  BCU,BMS,DTU,OBC
 SG_ VIU_stop_charging_cmd : 25|1@1+ (1,0) [0|1] ""  BCU,BMS,DTU,OBC
 SG_ VIU_vacation_mode_cmd : 26|1@1+ (1,0) [0|1] ""  BCU,BMS,DTU,OBC
 SG_ VIU_lock_charger_gun : 27|1@1+ (1,0) [0|1] ""  BCU,BMS,DTU,OBC
 SG_ VIU_veh_bootup_buz_cmd : 28|1@1+ (1,0) [0|1] ""  BCU,BMS,DTU,OBC
 SG_ VIU_veh_health_check_cmd : 29|1@1+ (1,0) [0|1] "Status"  BCU,BMS,DTU,OBC
 SG_ VIU_veh_sw_update_cmd : 30|1@1+ (1,0) [0|1] "Cmd"  BCU,BMS,DTU,OBC
 SG_ VIU_buzz_my_veh_cmd : 31|1@1+ (1,0) [0|1] "Cmd"  BCU,BMS,DTU,OBC
 SG_ VIU_pwr_state : 32|4@1+ (1,0) [0|15] "x"  BCU,BMS,DTU,OBC
 SG_ VIU_diagnostics_cmd : 36|1@1+ (1,0) [0|1] "x"  BCU,BMS,DTU,OBC
 SG_ VIC_keyfob_drop_chk_cmd : 39|1@1+ (1,0) [0|1] "x"  BCU,BMS,DTU,OBC
 SG_ VIC_super_critical_buzz_cmd : 40|1@1+ (1,0) [0|1] "x"  BCU,BMS,DTU,OBC
 SG_ VIC_critical_buzz_cmd : 41|1@1+ (1,0) [0|1] "x"  BCU,BMS,DTU,OBC
 SG_ VIC_warning1_buzz_cmd : 42|1@1+ (1,0) [0|1] "x"  BCU,BMS,DTU,OBC
 SG_ VIC_warning2_buzz_cmd : 43|1@1+ (1,0) [0|1] "x"  BCU,BMS,DTU,OBC
 SG_ VIC_demo_mode_cmd : 44|1@1+ (1,0) [0|1] "x"  BCU,BMS,DTU,OBC

BO_ 2020 VIU_PhyBMS_RqtMsg9: 8 VIU
 SG_ VIU_uds_frame_m9 : 0|64@1+ (1,0) [0|1.84467440737096E+019] ""  BMS

BO_ 2015 VIU_Func_RqtMsg12: 8 VIU
 SG_ VIU_uds_frame_m12 : 0|64@1+ (1,0) [0|1.84467440737096E+019] ""  ABS,BCU,BMS,DTU,OBC,PKE

BO_ 897 DTU_sensors_Msg2: 8 DTU
 SG_ DTU_throttle_position : 0|16@1+ (0.01,0) [0|65535] "%"  VIU
 SG_ DTU_dc_link_voltg : 16|16@1+ (0.01,0) [0|65535] "V"  VIU
 SG_ DTU_motor_rpm : 32|16@1+ (1,0) [0|65535] "RPM"  VIU
 SG_ DTU_kill_switch_status : 48|1@1+ (1,0) [0|1] ""  VIU
 SG_ DTU_brake_switch_status : 49|1@1+ (1,0) [0|1] ""  VIU
 SG_ DTU_clutch_switch_status : 50|1@1+ (1,0) [0|1] ""  VIU
 SG_ DTU_regen_status : 51|1@1+ (1,0) [0|1] ""  VIU
 SG_ DTU_start_switch_status : 53|1@1+ (1,0) [0|1] ""  VIU
 SG_ DTU_state : 56|8@1+ (1,0) [0|255] "count"  VIU

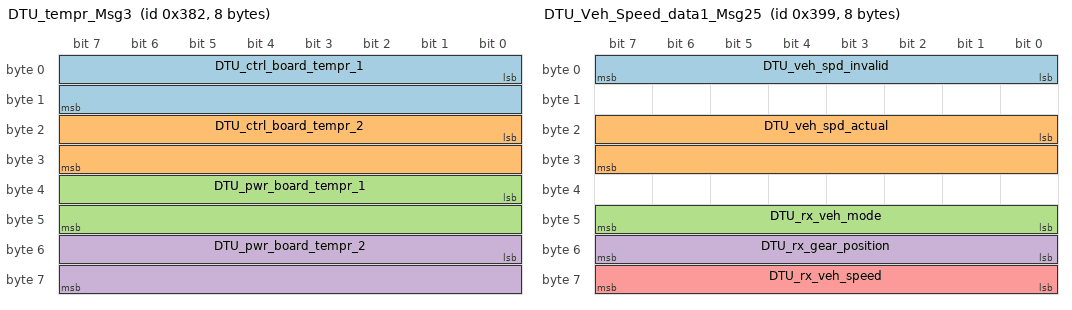
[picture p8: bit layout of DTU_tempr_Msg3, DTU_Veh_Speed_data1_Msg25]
BO_ 898 DTU_tempr_Msg3: 8 DTU
 SG_ DTU_ctrl_board_tempr_1 : 0|16@1- (1,0) [-32768|32767] "C"  VIU
 SG_ DTU_ctrl_board_tempr_2 : 16|16@1- (1,0) [-32768|32767] "C"  VIU
 SG_ DTU_pwr_board_tempr_1 : 32|16@1- (1,0) [-32768|32767] "C"  VIU
 SG_ DTU_pwr_board_tempr_2 : 48|16@1- (1,0) [-32768|32767] "C"  VIU

BO_ 899 DTU_tempr_Msg4: 8 DTU
 SG_ DTU_motor_tempr_1 : 0|16@1- (1,0) [-32768|32767] "C"  VIU
 SG_ DTU_motor_tempr_2 : 16|16@1- (1,0) [-32768|32767] "C"  VIU

BO_ 516 DTU_fault_Msg5: 8 DTU
 SG_ DTU_under_voltg_fault : 0|1@1+ (1,0) [0|1] ""  BMS,VIU
 SG_ DTU_over_voltg_fault : 1|1@1+ (1,0) [0|1] ""  BMS,VIU
 SG_ DTU_motor_over_tempr_fault : 2|1@1+ (1,0) [0|1] ""  BMS,VIU
 SG_ DTU_board_over_tempr_fault : 3|1@1+ (1,0) [0|1] ""  BMS,VIU
 SG_ DTU_high_rpm_fault : 4|1@1+ (1,0) [0|1] ""  BMS,VIU
 SG_ DTU_over_curr_fault : 5|1@1+ (1,0) [0|1] ""  BMS,VIU
 SG_ DTU_position_sensor_fault : 8|1@1+ (1,0) [0|1] ""  BMS,VIU
 SG_ DTU_throttle_limp_status : 9|1@1+ (1,0) [0|1] ""  BMS,VIU
 SG_ DTU_throttle_failure_status : 10|1@1+ (1,0) [0|1] ""  BMS,VIU
 SG_ DTU_sop_derating_flag : 11|1@1+ (1,0) [0|1] ""  BMS,VIU
 SG_ DTU_dtu_derating_flag : 12|1@1+ (1,0) [0|1] ""  BMS,VIU
 SG_ DTU_current_sensor_offset_fault : 13|1@1+ (1,0) [0|1] ""  BMS,VIU
 SG_ DTU_sop_charge_derating_flag : 14|1@1+ (1,0) [0|1] ""  BMS,VIU
 SG_ DTU_phase_a_oc : 16|1@1+ (1,0) [0|1] ""  BMS,VIU
 SG_ DTU_phase_b_oc : 17|1@1+ (1,0) [0|1] ""  BMS,VIU
 SG_ DTU_phase_c_oc : 18|1@1+ (1,0) [0|1] ""  BMS,VIU
 SG_ DTU_cmpss_status : 24|8@1+ (1,0) [0|255] ""  BMS,VIU
 SG_ DTU_gpio_driver_init_fail : 32|1@1+ (1,0) [0|1] ""  BMS,VIU
 SG_ DTU_pwm_driver_init_fail : 33|1@1+ (1,0) [0|1] ""  BMS,VIU
 SG_ DTU_adc_driver_init_fail : 34|1@1+ (1,0) [0|1] ""  BMS,VIU
 SG_ DTU_dac_driver_init_fail : 35|1@1+ (1,0) [0|1] ""  BMS,VIU
 SG_ DTU_cmpss_driver_init_fail : 36|1@1+ (1,0) [0|1] ""  BMS,VIU
 SG_ DTU_can_driver_init_fail : 37|1@1+ (1,0) [0|1] ""  BMS,VIU
 SG_ DTU_flash_driver_init_fail : 38|1@1+ (1,0) [0|1] ""  BMS,VIU
 SG_ DTU_timer_driver_init_fail : 39|1@1+ (1,0) [0|1] ""  BMS,VIU
 SG_ DTU_cla_driver_init_fail : 40|1@1+ (1,0) [0|1] ""  BMS,VIU
 SG_ DTU_wtdg_driver_init_fail : 41|1@1+ (1,0) [0|1] ""  BMS,VIU
 SG_ DTU_i2c_driver_init_fail : 42|1@1+ (1,0) [0|1] ""  BMS,VIU
 SG_ DTU_rtos_init_fail : 43|1@1+ (1,0) [0|1] ""  BMS,VIU
 SG_ DTU_controller_status : 48|2@1+ (1,0) [0|3] ""  BMS,VIU
 SG_ DTU_motor_status : 50|2@1+ (1,0) [0|3] ""  BMS,VIU
 SG_ DTU_motor_temp : 52|2@1+ (1,0) [0|3] ""  BMS,VIU
 SG_ DTU_Flash_corrupt_flag : 56|1@1+ (1,0) [0|1] ""  BMS,VIU
 SG_ DTU_wtdg_fail_flag0 : 57|1@1+ (1,0) [0|1] ""  BMS,VIU
 SG_ DTU_wtdg_fail_flag1 : 58|1@1+ (1,0) [0|1] ""  BMS,VIU
 SG_ DTU_cpu_fail_flag : 59|1@1+ (1,0) [0|1] ""  BMS,VIU
 SG_ DTU_nvm_write_fail_flag : 60|1@1+ (1,0) [0|1] ""  BMS,VIU
 SG_ DTU_nvm_read_fail_flag : 61|1@1+ (1,0) [0|1] ""  BMS,VIU
 SG_ DTU_auto_cal_success_fail_flag : 62|1@1+ (1,0) [0|1] ""  BMS,VIU
 SG_ DTU_critical_fault_flag : 63|1@1+ (1,0) [0|1] ""  BMS,VIU

 BO_ 921 DTU_Veh_Speed_data1_Msg25: 8 DTU
 SG_ DTU_veh_spd_invalid : 0|8@1+ (1,0) [0|255] "count"  VIU
 SG_ DTU_veh_spd_actual : 16|16@1+ (0.01,0) [0|65535] "kmph"  VIU
 SG_ DTU_rx_veh_mode : 40|8@1+ (1,0) [0|255] "count"  VIU
 SG_ DTU_rx_gear_position : 48|8@1+ (1,0) [0|255] "count"  VIU
 SG_ DTU_rx_veh_speed : 56|8@1+ (1,0) [0|255] "kmph"  VIU

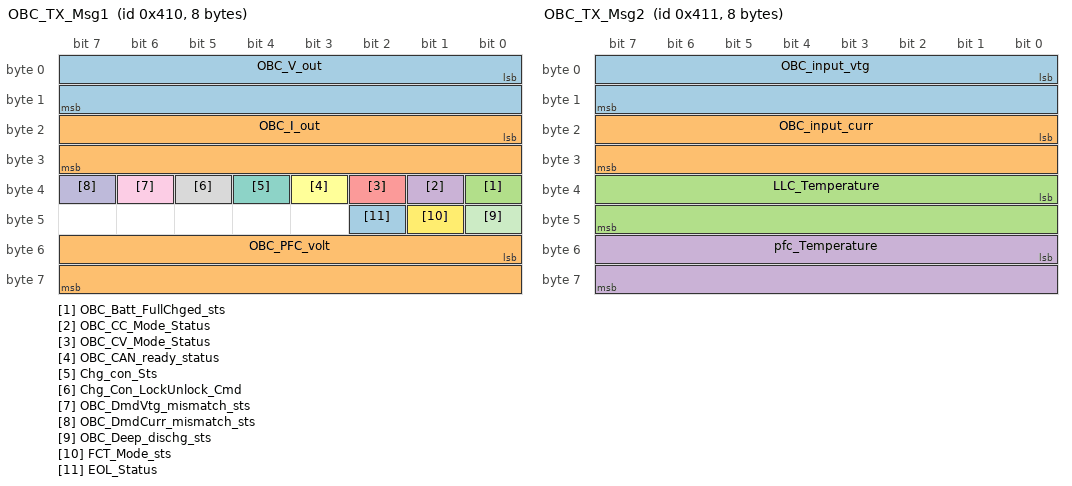
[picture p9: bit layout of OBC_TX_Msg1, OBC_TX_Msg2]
BO_ 1040 OBC_TX_Msg1: 8 OBC
 SG_ OBC_V_out : 0|16@1+ (0.1,0) [0|65535] "Volts"  BCU,BMS,VIU
 SG_ OBC_I_out : 16|16@1+ (1,0) [0|65535] "mAmp."  BCU,BMS,VIU
 SG_ OBC_Batt_FullChged_sts : 32|1@1+ (1,0) [0|1] ""  BCU,BMS,VIU
 SG_ OBC_CC_Mode_Status : 33|1@1+ (1,0) [0|1] ""  BCU,BMS,VIU
 SG_ OBC_CV_Mode_Status : 34|1@1+ (1,0) [0|1] ""  BCU,BMS,VIU
 SG_ OBC_CAN_ready_status : 35|1@1+ (1,0) [0|1] ""  BCU,BMS,VIU
 SG_ Chg_con_Sts : 36|1@1+ (1,0) [0|1] ""  BCU,BMS,VIU
 SG_ Chg_Con_LockUnlock_Cmd : 37|1@1+ (1,0) [0|1] ""  BCU,BMS,VIU
 SG_ OBC_DmdVtg_mismatch_sts : 38|1@1+ (1,0) [0|1] ""  BCU,BMS,VIU
 SG_ OBC_DmdCurr_mismatch_sts : 39|1@1+ (1,0) [0|1] ""  BCU,BMS,VIU
 SG_ OBC_Deep_dischg_sts : 40|1@1+ (1,0) [0|1] ""  BCU,BMS,VIU
 SG_ FCT_Mode_sts : 41|1@1+ (1,0) [0|1] ""  BCU,BMS,VIU
 SG_ EOL_Status : 42|1@1+ (1,0) [0|1] ""  BCU,BMS,VIU
 SG_ OBC_PFC_volt : 48|16@1+ (0.1,0) [0|65535] "volts"  BCU,BMS,VIU

BO_ 1041 OBC_TX_Msg2: 8 OBC
 SG_ OBC_input_vtg : 0|16@1+ (0.1,0) [0|65535] "Volts"  BMS,VIU
 SG_ OBC_input_curr : 16|16@1+ (1,0) [0|65535] "mAmps"  BMS,VIU
 SG_ LLC_Temperature : 32|16@1- (1,0) [-32768|32767] "Deg C"  BMS,VIU
 SG_ pfc_Temperature : 48|16@1- (1,0) [-32768|32767] "Deg C"  BMS,VIU

BO_ 517 OBC_Fault_Evt_Msg15: 8 OBC
 SG_ OBC_hw_failure_Short_Ckt : 0|1@1+ (1,0) [0|1] ""  BMS,VIU
 SG_ OBC_Temperature_fault : 1|1@1+ (1,0) [0|1] ""  BMS,VIU
 SG_ OBC_Input_Over_Voltage : 2|1@1+ (1,0) [0|1] ""  BMS,VIU
 SG_ OBC_Input_Under_Voltage : 3|1@1+ (1,0) [0|1] ""  BMS,VIU
 SG_ OBC_Output_Voltage_high : 4|1@1+ (1,0) [0|1] ""  BMS,VIU
 SG_ OBC_Line_Neutral_Interchange : 6|1@1+ (1,0) [0|1] ""  BMS,VIU
 SG_ OBC_Earth_open : 7|1@1+ (1,0) [0|1] ""  BMS,VIU
 SG_ OBC_Input_Over_Voltage_Alarm : 8|1@1+ (1,0) [0|1] ""  BMS,VIU
 SG_ OBC_Input_Under_Voltage_Alarm : 9|1@1+ (1,0) [0|1] ""  BMS,VIU
 SG_ OBC_PFC_Currnet_Peak : 10|1@1+ (1,0) [0|1] ""  BMS,VIU
 SG_ OBC_Precharge_flag : 11|1@1+ (1,0) [0|1] ""  BMS,VIU
 SG_ OBC_PFC_DC_High : 12|1@1+ (1,0) [0|1] ""  BMS,VIU
 SG_ OBC_PFC_DC_Dip : 13|1@1+ (1,0) [0|1] ""  BMS,VIU
 SG_ OBC_Short_Ckt_2 : 14|1@1+ (1,0) [0|1] ""  BMS,VIU
 SG_ LLC_Temp_sensor_fault : 15|1@1+ (1,0) [0|1] ""  BMS,VIU
 SG_ PFC_Temp_sensor_fault : 16|1@1+ (1,0) [0|1] ""  BMS,VIU
 SG_ alarm_OBC_shutdown_peak_curr : 17|1@1+ (1,0) [0|1] ""  BMS,VIU
 SG_ PFC_Volt_ok : 18|1@1+ (1,0) [0|1] ""  BMS,VIU
 SG_ Pfc_ic_off : 19|1@1+ (1,0) [0|1] ""  BMS,VIU
 SG_ input_ov_deep_disch : 20|1@1+ (1,0) [0|1] ""  BMS,VIU
 SG_ Stop_chg_can_fail_msg15 : 21|1@1+ (1,0) [0|1] ""  BMS,VIU
 SG_ OBC_Input_UV_inst : 22|1@1+ (1,0) [0|1] ""  BMS,VIU

BO_ 1056 OBC_Heart_beat_Msg16: 8 DTU
 SG_ ECU_Name : 0|8@1+ (1,0) [0|255] ""  BMS,OBC,PKE,VIU
 SG_ Rolling_Counter : 8|8@1+ (1,0) [0|255] ""  BMS,OBC,PKE,VIU

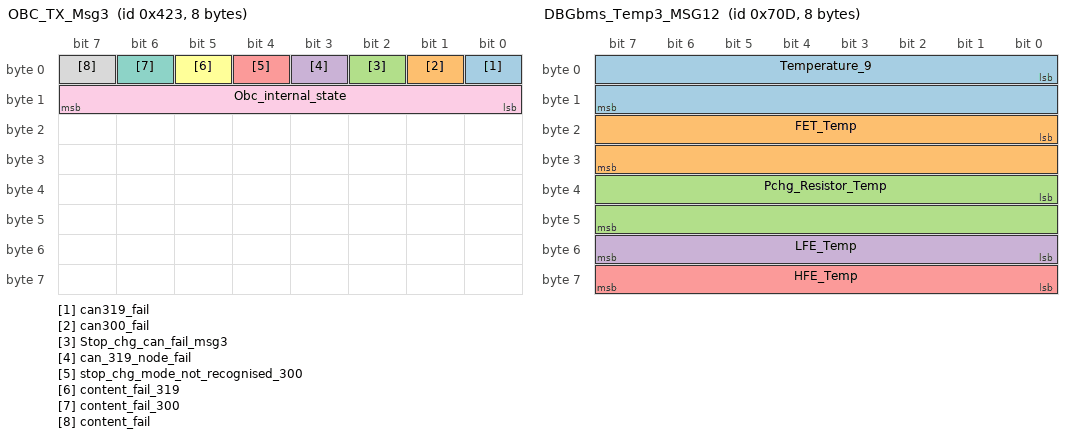
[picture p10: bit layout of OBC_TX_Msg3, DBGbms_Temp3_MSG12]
BO_ 1059 OBC_TX_Msg3: 8 OBC
 SG_ can319_fail : 0|1@1+ (1,0) [0|1] ""  BMS,VIU
 SG_ can300_fail : 1|1@1+ (1,0) [0|1] ""  BMS,VIU
 SG_ Stop_chg_can_fail_msg3 : 2|1@1+ (1,0) [0|1] ""  BMS,VIU
 SG_ can_319_node_fail : 3|1@1+ (1,0) [0|1] ""  BMS,VIU
 SG_ stop_chg_mode_not_recognised_300 : 4|1@1+ (1,0) [0|1] ""  BMS,VIU
 SG_ content_fail_319 : 5|1@1+ (1,0) [0|1] ""  BMS,VIU
 SG_ content_fail_300 : 6|1@1+ (1,0) [0|1] ""  BMS,VIU
 SG_ content_fail : 7|1@1+ (1,0) [0|1] ""  BMS,VIU
 SG_ Obc_internal_state : 8|8@1+ (1,0) [0|255] ""  BMS,VIU

BO_ 1794 DBGbms_CoolSysTemp_MSG1: 8 BMS
 SG_ CS_Temperature : 0|16@1- (0.01,0) [-32768|32767] "Deg C"  VIU
 SG_ Temperature10 : 16|16@1- (0.01,0) [-32768|32767] "Deg C"  VIU
 SG_ Temperature11 : 32|16@1- (0.01,0) [-32768|32767] "Deg C"  VIU
 SG_ Temperature12 : 48|16@1- (0.01,0) [-32768|32767] "Deg C"  VIU

BO_ 1795 DBGbms_Isovtg_MSG2: 8 BMS
 SG_ Iso_Vtg_1 : 0|32@1- (1,0) [-2147483648|2147483647] "mV"  VIU
 SG_ Iso_Vtg_2 : 32|32@1- (1,0) [-2147483648|2147483647] "mV"  VIU

BO_ 1796 DBGbms_Cellvtg1_MSG3: 8 BMS
 SG_ Cell_1 : 0|16@1+ (1,0) [0|65535] "mV"  VIU
 SG_ Cell_2 : 16|16@1+ (1,0) [0|65535] "mV"  VIU
 SG_ Cell_3 : 32|16@1+ (1,0) [0|65535] "mV"  VIU
 SG_ Cell_4 : 48|16@1+ (1,0) [0|65535] "mV"  VIU

BO_ 1797 DBGbms_Cellvtg2_MSG4: 8 BMS
 SG_ Cell_5 : 0|16@1+ (1,0) [0|65535] "mV"  VIU
 SG_ Cell_6 : 16|16@1+ (1,0) [0|65535] "mV"  VIU
 SG_ Cell_7 : 32|16@1+ (1,0) [0|65535] "mV"  VIU
 SG_ Cell_8 : 48|16@1+ (1,0) [0|65535] "mV"  VIU

BO_ 1798 DBGbms_Cellvtg3_MSG5: 8 BMS
 SG_ Cell_9 : 0|16@1+ (1,0) [0|65535] "mV"  VIU
 SG_ Cell_10 : 16|16@1+ (1,0) [0|65535] "mV"  VIU
 SG_ Cell_11 : 32|16@1+ (1,0) [0|65535] "mV"  VIU
 SG_ Cell_12 : 48|16@1+ (1,0) [0|65535] "mV"  VIU

BO_ 1799 DBGbms_Cellvtg4_MSG6: 8 BMS
 SG_ Cell_13 : 0|16@1+ (1,0) [0|65535] "mV"  VIU
 SG_ Cell_14 : 16|16@1+ (1,0) [0|65535] "mV"  VIU
 SG_ Cell_15 : 32|16@1+ (1,0) [0|65535] "mV"  VIU
 SG_ Cell_16 : 48|16@1+ (1,0) [0|65535] "mV"  VIU

BO_ 1800 DBGbms_Cellvtg5_MSG7: 8 BMS
 SG_ Cell_17 : 0|16@1+ (1,0) [0|65535] "mV"  VIU
 SG_ Cell_18 : 16|16@1+ (1,0) [0|65535] "mV"  VIU
 SG_ Cell_19 : 32|16@1+ (1,0) [0|65535] "mV"  VIU
 SG_ Cell_20 : 48|16@1+ (1,0) [0|65535] "mV"  VIU

BO_ 1801 DBGbms_Cellvtg6_MSG8: 8 BMS
 SG_ Cell_21 : 0|16@1+ (1,0) [0|65535] "mV"  VIU
 SG_ Cell_22 : 16|16@1+ (1,0) [0|65535] "mV"  VIU
 SG_ Cell_23 : 32|16@1+ (1,0) [0|65535] "mV"  VIU
 SG_ Cell_24 : 48|16@1+ (1,0) [0|65535] "mV"  VIU

BO_ 1802 DBGbms_Cellvtg7_MSG9: 8 BMS
 SG_ Cell_25 : 0|16@1+ (1,0) [0|65535] "mV"  VIU
 SG_ Cell_26 : 16|16@1+ (1,0) [0|65535] "mV"  VIU
 SG_ Cell_27 : 32|16@1+ (1,0) [0|65535] "mV"  VIU
 SG_ Cell_28 : 48|16@1+ (1,0) [0|65535] "mV"  VIU

BO_ 1803 DBGbms_Temp1_MSG10: 8 BMS
 SG_ Temperature_1 : 0|16@1- (0.01,0) [-32768|32767] "Deg C"  VIU
 SG_ Temperature_2 : 16|16@1- (0.01,0) [-32768|32767] "Deg C"  VIU
 SG_ Temperature_3 : 32|16@1- (0.01,0) [-32768|32767] "Deg C"  VIU
 SG_ Temperature_4 : 48|16@1- (0.01,0) [-32768|32767] "Deg C"  VIU

BO_ 1804 DBGbms_Temp2_MSG11: 8 BMS
 SG_ Temperature_5 : 0|16@1- (0.01,0) [-32768|32767] "Deg C"  VIU
 SG_ Temperature_6 : 16|16@1- (0.01,0) [-32768|32767] "Deg C"  VIU
 SG_ Temperature_7 : 32|16@1- (0.01,0) [-32768|32767] "Deg C"  VIU
 SG_ Temperature_8 : 48|16@1- (0.01,0) [-32768|32767] "Deg C"  VIU

BO_ 1805 DBGbms_Temp3_MSG12: 8 BMS
 SG_ Temperature_9 : 0|16@1- (0.01,0) [-32768|32767] "Deg C"  VIU
 SG_ FET_Temp : 16|16@1- (0.01,0) [-32768|32767] "Deg C"  VIU
 SG_ Pchg_Resistor_Temp : 32|16@1- (0.01,0) [-32768|32767] "Deg C"  VIU
 SG_ LFE_Temp : 48|8@1- (1,0) [-128|127] "Deg C"  VIU
 SG_ HFE_Temp : 56|8@1- (1,0) [-128|127] "Deg C"  VIU

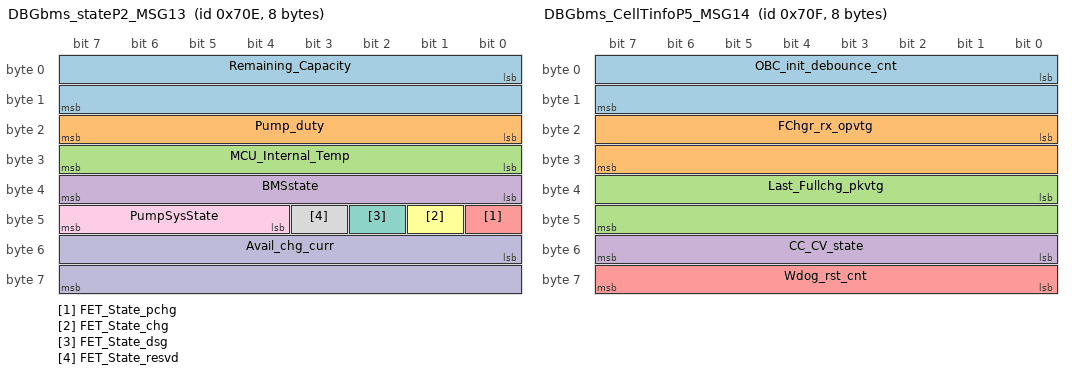
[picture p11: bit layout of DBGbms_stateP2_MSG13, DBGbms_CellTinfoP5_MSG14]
BO_ 1806 DBGbms_stateP2_MSG13: 8 BMS
 SG_ Remaining_Capacity : 0|16@1+ (1,0) [0|65535] "mAh"  VIU
 SG_ Pump_duty : 16|8@1+ (1,0) [0|255] "percent"  VIU
 SG_ MCU_Internal_Temp : 24|8@1+ (1,0) [0|255] "Deg C"  VIU
 SG_ BMSstate : 32|8@1+ (1,0) [0|255] "Enum"  VIU
 SG_ FET_State_pchg : 40|1@1+ (1,0) [0|1] "Status"  VIU
 SG_ FET_State_chg : 41|1@1+ (1,0) [0|1] "Status"  VIU
 SG_ FET_State_dsg : 42|1@1+ (1,0) [0|1] "Status"  VIU
 SG_ FET_State_resvd : 43|1@1+ (1,0) [0|1] "Status"  VIU
 SG_ PumpSysState : 44|4@1+ (1,0) [0|15] "x"  VIU
 SG_ Avail_chg_curr : 48|16@1+ (0.01,0) [0|65535] "A"  VIU

BO_ 1807 DBGbms_CellTinfoP5_MSG14: 8 BMS
 SG_ OBC_init_debounce_cnt : 0|16@1+ (1,0) [0|65535] "x"  VIU
 SG_ FChgr_rx_opvtg : 16|16@1+ (0.1,0) [0|65535] "V"  VIU
 SG_ Last_Fullchg_pkvtg : 32|16@1+ (0.1,0) [0|65535] "V"  VIU
 SG_ CC_CV_state : 48|8@1+ (1,0) [0|255] "x"  VIU
 SG_ Wdog_rst_cnt : 56|8@1+ (1,0) [0|255] "x"  VIU

BO_ 1808 DBGbms_AFEVtgcurr_MSG15: 8 BMS
 SG_ LowHost_Current : 0|16@1- (1,0) [-32768|32767] "cA"  VIU
 SG_ UppHost_Current : 16|16@1- (1,0) [-32768|32767] "cA"  VIU
 SG_ LowHost_Voltage : 32|16@1+ (1,0) [0|65535] "mV"  VIU
 SG_ UppHost_Voltage : 48|16@1+ (1,0) [0|65535] "mV"  VIU

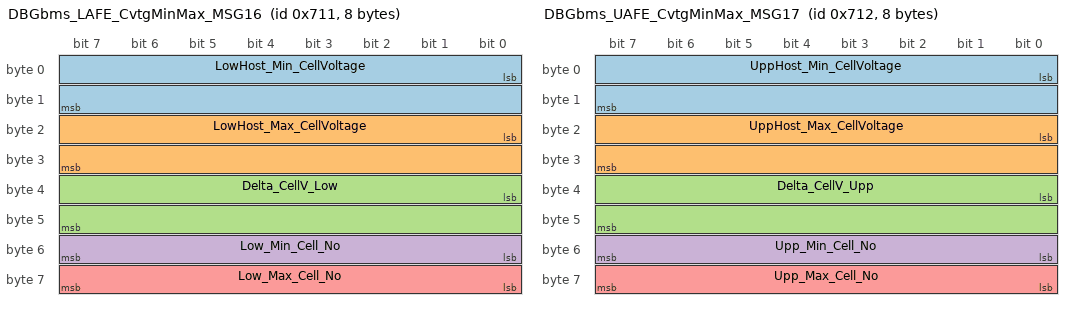
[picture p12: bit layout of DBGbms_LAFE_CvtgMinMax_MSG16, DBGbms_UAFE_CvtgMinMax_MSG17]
BO_ 1809 DBGbms_LAFE_CvtgMinMax_MSG16: 8 BMS
 SG_ LowHost_Min_CellVoltage : 0|16@1+ (1,0) [0|65535] "mV"  VIU
 SG_ LowHost_Max_CellVoltage : 16|16@1+ (1,0) [0|65535] "mV"  VIU
 SG_ Delta_CellV_Low : 32|16@1+ (1,0) [0|65535] "mV"  VIU
 SG_ Low_Min_Cell_No : 48|8@1+ (1,0) [0|255] "x"  VIU
 SG_ Low_Max_Cell_No : 56|8@1+ (1,0) [0|255] "x"  VIU

BO_ 1810 DBGbms_UAFE_CvtgMinMax_MSG17: 8 BMS
 SG_ UppHost_Min_CellVoltage : 0|16@1+ (1,0) [0|65535] "mV"  VIU
 SG_ UppHost_Max_CellVoltage : 16|16@1+ (1,0) [0|65535] "mV"  VIU
 SG_ Delta_CellV_Upp : 32|16@1+ (1,0) [0|65535] "mV"  VIU
 SG_ Upp_Min_Cell_No : 48|8@1+ (1,0) [0|255] "x"  VIU
 SG_ Upp_Max_Cell_No : 56|8@1+ (1,0) [0|255] "x"  VIU

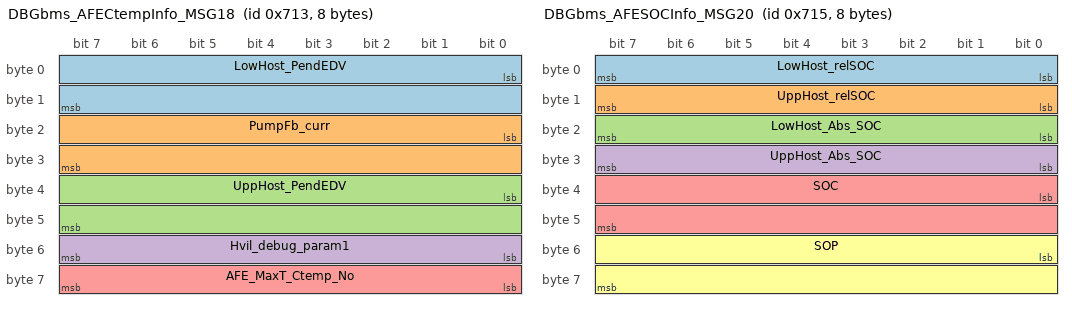
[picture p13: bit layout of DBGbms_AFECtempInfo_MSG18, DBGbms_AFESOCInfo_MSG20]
BO_ 1811 DBGbms_AFECtempInfo_MSG18: 8 BMS
 SG_ LowHost_PendEDV : 0|16@1+ (0.001,0) [0|65535] "V"  VIU
 SG_ PumpFb_curr : 16|16@1- (1,0) [-32768|32767] "mA"  VIU
 SG_ UppHost_PendEDV : 32|16@1+ (0.001,0) [0|65535] "V"  VIU
 SG_ Hvil_debug_param1 : 48|8@1+ (1,0) [0|255] "x"  VIU
 SG_ AFE_MaxT_Ctemp_No : 56|8@1+ (1,0) [0|255] "x"  VIU

BO_ 1812 DBGbms_AFECapacityInfo_MSG19: 8 BMS
 SG_ LowHost_RemCap : 0|16@1+ (0.01,0) [0|65535] "Ah"  VIU
 SG_ UppHost_RemCap : 16|16@1+ (0.01,0) [0|65535] "Ah"  VIU
 SG_ LowHost_Full_Chg_Cap : 32|16@1+ (0.01,0) [0|65535] "Ah"  VIU
 SG_ UppHost_Full_Chg_Cap : 48|16@1+ (0.01,0) [0|65535] "Ah"  VIU

BO_ 1813 DBGbms_AFESOCInfo_MSG20: 8 BMS
 SG_ LowHost_relSOC : 0|8@1+ (1,0) [0|255] "percent"  VIU
 SG_ UppHost_relSOC : 8|8@1+ (1,0) [0|255] "percent"  VIU
 SG_ LowHost_Abs_SOC : 16|8@1+ (1,0) [0|255] "percent"  VIU
 SG_ UppHost_Abs_SOC : 24|8@1+ (1,0) [0|255] "percent"  VIU
 SG_ SOC : 32|16@1+ (1,0) [0|65535] "percent"  VIU
 SG_ SOP : 48|16@1+ (1,0) [0|65535] "Watts"  VIU

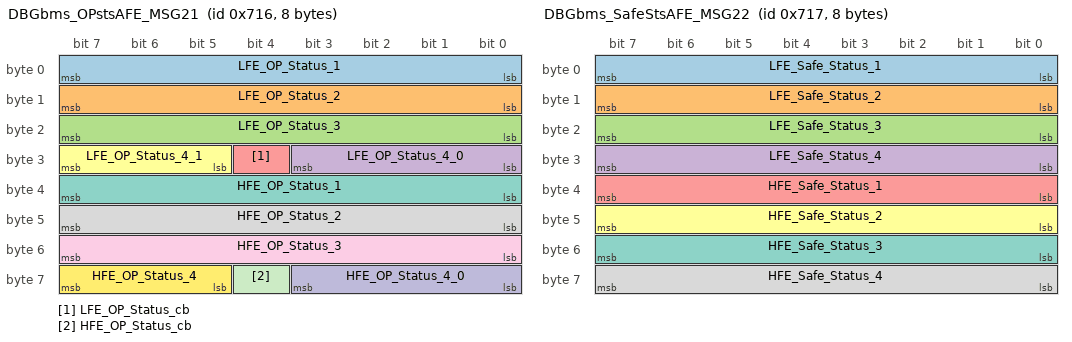
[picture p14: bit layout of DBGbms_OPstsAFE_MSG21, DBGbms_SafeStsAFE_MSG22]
BO_ 1814 DBGbms_OPstsAFE_MSG21: 8 BMS
 SG_ LFE_OP_Status_1 : 0|8@1+ (1,0) [0|255] "Binary Data"  VIU
 SG_ LFE_OP_Status_2 : 8|8@1+ (1,0) [0|255] "Binary Data"  VIU
 SG_ LFE_OP_Status_3 : 16|8@1+ (1,0) [0|255] "Binary Data"  VIU
 SG_ LFE_OP_Status_4_0 : 24|4@1+ (1,0) [0|15] "Binary Data"  VIU
 SG_ LFE_OP_Status_cb : 28|1@1+ (1,0) [0|1] "Binary Data"  VIU
 SG_ LFE_OP_Status_4_1 : 29|3@1+ (1,0) [0|7] "Binary Data"  VIU
 SG_ HFE_OP_Status_1 : 32|8@1+ (1,0) [0|255] "Binary Data"  VIU
 SG_ HFE_OP_Status_2 : 40|8@1+ (1,0) [0|255] "Binary Data"  VIU
 SG_ HFE_OP_Status_3 : 48|8@1+ (1,0) [0|255] "Binary Data"  VIU
 SG_ HFE_OP_Status_4_0 : 56|4@1+ (1,0) [0|15] "Binary Data"  VIU
 SG_ HFE_OP_Status_cb : 60|1@1+ (1,0) [0|1] "Binary Data"  VIU
 SG_ HFE_OP_Status_4 : 61|3@1+ (1,0) [0|7] "Binary Data"  VIU

BO_ 1815 DBGbms_SafeStsAFE_MSG22: 8 BMS
 SG_ LFE_Safe_Status_1 : 0|8@1+ (1,0) [0|255] "Binary Data"  VIU
 SG_ LFE_Safe_Status_2 : 8|8@1+ (1,0) [0|255] "Binary Data"  VIU
 SG_ LFE_Safe_Status_3 : 16|8@1+ (1,0) [0|255] "Binary Data"  VIU
 SG_ LFE_Safe_Status_4 : 24|8@1+ (1,0) [0|255] "Binary Data"  VIU
 SG_ HFE_Safe_Status_1 : 32|8@1+ (1,0) [0|255] "Binary Data"  VIU
 SG_ HFE_Safe_Status_2 : 40|8@1+ (1,0) [0|255] "Binary Data"  VIU
 SG_ HFE_Safe_Status_3 : 48|8@1+ (1,0) [0|255] "Binary Data"  VIU
 SG_ HFE_Safe_Status_4 : 56|8@1+ (1,0) [0|255] "Binary Data"  VIU

BO_ 1816 DBGbms_MCUsts_MSG23: 8 BMS
 SG_ chg_mcufet_inv : 0|1@1+ (1,0) [0|1] "x"  VIU
 SG_ dsg_mcufet_inv : 1|1@1+ (1,0) [0|1] "x"  VIU
 SG_ dsgfet_ovrlfb : 2|1@1+ (1,0) [0|1] "x"  VIU
 SG_ scd_in_inv_fb : 3|1@1+ (1,0) [0|1] "x"  VIU
 SG_ calib_mode_flg : 4|1@1+ (1,0) [0|1] "x"  VIU
 SG_ state_crit_bmsInd : 5|1@1+ (1,0) [0|1] "x"  VIU
 SG_ trip_action_bmsInd : 6|2@1+ (1,0) [0|3] "x"  VIU
 SG_ chg_detect_bmsInd : 8|1@1+ (1,0) [0|1] "x"  VIU
 SG_ aps_state_bmsInd : 9|1@1+ (1,0) [0|1] "x"  VIU
 SG_ prodmode_bmsInd : 10|1@1+ (1,0) [0|1] "x"  VIU
 SG_ lh_cb_act_bmsInd : 11|1@1+ (1,0) [0|1] "x"  VIU
 SG_ uh_cb_act_bmsInd : 12|1@1+ (1,0) [0|1] "x"  VIU
 SG_ pb_lpk_bmsInd : 13|1@1+ (1,0) [0|1] "x"  VIU
 SG_ pb_upk_bmsInd : 14|1@1+ (1,0) [0|1] "x"  VIU
 SG_ prevcyc_mcu_shutdwn : 15|1@1+ (1,0) [0|1] "x"  VIU
 SG_ PchgHit_PK_Current : 16|16@1- (0.01,0) [-32768|32767] "A"  VIU
 SG_ Pchg_allowed_pk_current : 32|32@1- (0.001,0) [-2147483648|2147483647] "A"  VIU

BO_ 1817 DBGbms_execTimeTasks_MSG24: 8 BMS
 SG_ ExecTime_UDSTsk : 0|16@1+ (2.5,0) [0|65535] "us"  VIU
 SG_ ExecTime_AFETsk : 16|16@1+ (0.01,0) [0|65535] "ms"  VIU
 SG_ ExecTime_TransTsk : 32|16@1+ (2.5,0) [0|65535] "us"  VIU
 SG_ ExecTime_SOCTsk : 48|16@1+ (0.01,0) [0|65535] "ms"  VIU

BO_ 1818 DBGbms_StackPk1_MSG25: 8 BMS
 SG_ StackPk_DiagTsk : 0|16@1+ (1,0) [0|65535] "bytes"  VIU
 SG_ StackPk_StateTransTsk : 16|16@1+ (1,0) [0|65535] "bytes"  VIU
 SG_ CAN_Tx_Failcnt : 32|16@1+ (1,0) [0|65535] "bytes"  VIU
 SG_ i2c1_pk_tout : 48|16@1+ (1,0) [0|65535] "bytes"  VIU

BO_ 1819 DBGbms_StackPk2_MSG26: 8 BMS
 SG_ StackPk_CANTsk : 0|16@1+ (1,0) [0|65535] "bytes"  VIU
 SG_ StackPk_AFETsk : 16|16@1+ (1,0) [0|65535] "bytes"  VIU
 SG_ StackPk_ADCTsk : 32|16@1+ (1,0) [0|65535] "bytes"  VIU
 SG_ dtdt_1c_flag : 48|16@1+ (1,0) [0|65535] "bytes"  VIU

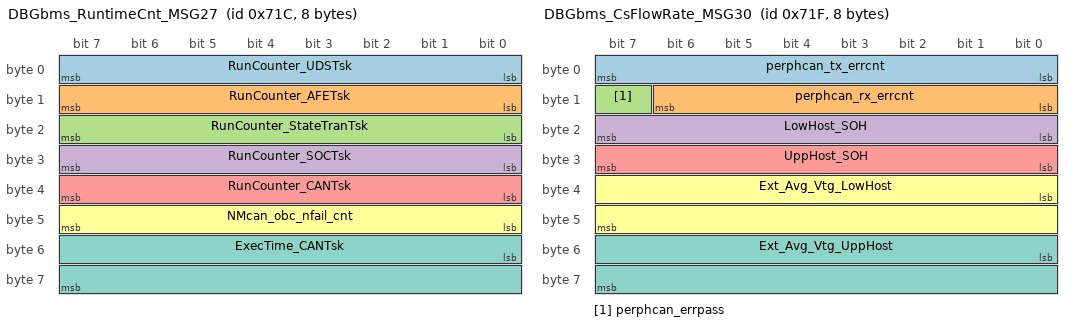
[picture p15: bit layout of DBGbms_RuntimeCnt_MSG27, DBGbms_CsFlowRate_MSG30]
BO_ 1820 DBGbms_RuntimeCnt_MSG27: 8 BMS
 SG_ RunCounter_UDSTsk : 0|8@1+ (1,0) [0|255] "x"  VIU
 SG_ RunCounter_AFETsk : 8|8@1+ (1,0) [0|255] "x"  VIU
 SG_ RunCounter_StateTranTsk : 16|8@1+ (1,0) [0|255] "x"  VIU
 SG_ RunCounter_SOCTsk : 24|8@1+ (1,0) [0|255] "x"  VIU
 SG_ RunCounter_CANTsk : 32|8@1+ (1,0) [0|255] "x"  VIU
 SG_ NMcan_obc_nfail_cnt : 40|8@1+ (1,0) [0|255] "x"  VIU
 SG_ ExecTime_CANTsk : 48|16@1+ (0.01,0) [0|65535] "ms"  VIU

BO_ 1821 DBGbms_WarnGaugeSts_MSG28: 8 BMS
 SG_ cov_warnbms : 0|1@1+ (1,0) [0|1] "Status"  VIU
 SG_ cuv_warnbms : 1|1@1+ (1,0) [0|1] "Status"  VIU
 SG_ del_v_warnbms : 2|1@1+ (1,0) [0|1] "Status"  VIU
 SG_ cotd_warnbms : 3|1@1+ (1,0) [0|1] "Status"  VIU
 SG_ cutd_warnbms : 4|1@1+ (1,0) [0|1] "Status"  VIU
 SG_ del_ct_warnbms : 5|1@1+ (1,0) [0|1] "Status"  VIU
 SG_ fot_warnbms : 6|1@1+ (1,0) [0|1] "Status"  VIU
 SG_ csot_warnbms : 7|1@1+ (1,0) [0|1] "Status"  VIU
 SG_ afedieot_warnbms : 8|1@1+ (1,0) [0|1] "Status"  VIU
 SG_ occ_warnbms : 9|1@1+ (1,0) [0|1] "Status"  VIU
 SG_ ocd_warnbms : 10|1@1+ (1,0) [0|1] "Status"  VIU
 SG_ pusoc_warnbms : 11|1@1+ (1,0) [0|1] "Status"  VIU
 SG_ hvil_warnbms : 12|1@1+ (1,0) [0|1] "Status"  VIU
 SG_ imd_warnbms : 13|1@1+ (1,0) [0|1] "Status"  VIU
 SG_ crit_lvl1_warnbms : 14|1@1+ (1,0) [0|1] "Status"  VIU
 SG_ crit_lvl2_warnbms : 15|1@1+ (1,0) [0|1] "Status"  VIU
 SG_ hostl_i2c_warnbms : 16|1@1+ (1,0) [0|1] "Status"  VIU
 SG_ hostu_i2c_warnbms : 17|1@1+ (1,0) [0|1] "Status"  VIU
 SG_ pump_oload_warnbms : 18|1@1+ (1,0) [0|1] "Status"  VIU
 SG_ dpdsg_warnbms : 19|1@1+ (1,0) [0|1] "Status"  VIU
 SG_ cotc_warnbms : 20|1@1+ (1,0) [0|1] "Status"  VIU
 SG_ cutc_warnbms : 21|1@1+ (1,0) [0|1] "Status"  VIU
 SG_ Reset_cause_bms : 24|8@1+ (1,0) [0|255] "Status"  VIU
 SG_ LFE_GaugeSts_1 : 32|8@1+ (1,0) [0|255] "Binary Data"  VIU
 SG_ LFE_GaugeSts_2 : 40|8@1+ (1,0) [0|255] "Binary Data"  VIU
 SG_ HFE_GaugeSts_1 : 48|8@1+ (1,0) [0|255] "Binary Data"  VIU
 SG_ HFE_GaugeSts_2 : 56|8@1+ (1,0) [0|255] "Binary Data"  VIU

BO_ 1822 DBGbms_Faults_MSG29: 8 BMS
 SG_ afe_cov_fltbms : 0|1@1+ (1,0) [0|1] "Status"  VIU
 SG_ afe_cuv_fltbms : 1|1@1+ (1,0) [0|1] "Status"  VIU
 SG_ afe_cot_chg_fltbms : 2|1@1+ (1,0) [0|1] "Status"  VIU
 SG_ afe_cot_dchg_fltbms : 3|1@1+ (1,0) [0|1] "Status"  VIU
 SG_ afe_cut_chg_fltbms : 4|1@1+ (1,0) [0|1] "Status"  VIU
 SG_ afe_cut_dchg_fltbms : 5|1@1+ (1,0) [0|1] "Status"  VIU
 SG_ afe_oc_chg_fltbms : 6|1@1+ (1,0) [0|1] "Status"  VIU
 SG_ afe_oc_dchg_fltbms : 7|1@1+ (1,0) [0|1] "Status"  VIU
 SG_ afe_sc_detect_fltbms : 8|1@1+ (1,0) [0|1] "Status"  VIU
 SG_ afe_oload_detect_fltbms : 9|1@1+ (1,0) [0|1] "Status"  VIU
 SG_ afe_fet_off_fltbms : 10|1@1+ (1,0) [0|1] "Status"  VIU
 SG_ afe_oc_fltbms : 11|1@1+ (1,0) [0|1] "Status"  VIU
 SG_ afe_otf_fltbms : 12|1@1+ (1,0) [0|1] "Status"  VIU
 SG_ afe_chgfoff_fltbms : 13|1@1+ (1,0) [0|1] "Status"  VIU
 SG_ afe_dsgfoff_fltbms : 14|1@1+ (1,0) [0|1] "Status"  VIU
 SG_ ddsg_fltbms : 18|1@1+ (1,0) [0|1] "Status"  VIU
 SG_ del_cv_fltbms : 19|1@1+ (1,0) [0|1] "Status"  VIU
 SG_ pchg_tout_fltbms : 20|1@1+ (1,0) [0|1] "Status"  VIU
 SG_ del_ct_fltbms : 21|1@1+ (1,0) [0|1] "Status"  VIU
 SG_ hostl_i2c_fltbms : 22|1@1+ (1,0) [0|1] "Status"  VIU
 SG_ hostu_i2c_fltbms : 23|1@1+ (1,0) [0|1] "Status"  VIU
 SG_ cot_chg_fltbms : 24|1@1+ (1,0) [0|1] "Status"  VIU
 SG_ cot_dsg_fltbms : 25|1@1+ (1,0) [0|1] "Status"  VIU
 SG_ cut_chg_fltbms : 26|1@1+ (1,0) [0|1] "Status"  VIU
 SG_ cut_dsg_fltbms : 27|1@1+ (1,0) [0|1] "Status"  VIU
 SG_ fot_fltbms : 28|1@1+ (1,0) [0|1] "Status"  VIU
 SG_ csot_fltbms : 29|1@1+ (1,0) [0|1] "Status"  VIU
 SG_ afedieot_fltbms : 30|1@1+ (1,0) [0|1] "Status"  VIU
 SG_ imd_fltbms : 31|1@1+ (1,0) [0|1] "Status"  VIU
 SG_ hostl_fail_fltbms : 32|1@1+ (1,0) [0|1] "Status"  VIU
 SG_ hostu_fail_fltbms : 33|1@1+ (1,0) [0|1] "Status"  VIU
 SG_ ctow_fail_fltbms : 34|1@1+ (1,0) [0|1] "Status"  VIU
 SG_ nctow_fail_fltbms : 35|1@1+ (1,0) [0|1] "Status"  VIU
 SG_ cs_ic_fail_fltbms : 36|1@1+ (1,0) [0|1] "Status"  VIU
 SG_ imd_ic_fail_fltbms : 37|1@1+ (1,0) [0|1] "Status"  VIU
 SG_ ftow_fail_fltbms : 38|1@1+ (1,0) [0|1] "Status"  VIU
 SG_ cstow_fail_fltbms : 39|1@1+ (1,0) [0|1] "Status"  VIU
 SG_ aps_scd_fltbms : 40|1@1+ (1,0) [0|1] "Status"  VIU
 SG_ aps_ot_fltbms : 41|1@1+ (1,0) [0|1] "Status"  VIU
 SG_ aps_ov_fltbms : 42|1@1+ (1,0) [0|1] "Status"  VIU
 SG_ aps_oc_fltbms : 43|1@1+ (1,0) [0|1] "Status"  VIU
 SG_ fetchg_short_fltbms : 44|1@1+ (1,0) [0|1] "Status"  VIU
 SG_ fetdsg_short_fltbms : 45|1@1+ (1,0) [0|1] "Status"  VIU
 SG_ pchg_pk_fltbms : 46|1@1+ (1,0) [0|1] "Status"  VIU
 SG_ crit_rel_fltbms : 47|1@1+ (1,0) [0|1] "Status"  VIU
 SG_ pchg_rot_fltbms : 48|1@1+ (1,0) [0|1] "Status"  VIU
 SG_ pchg_rtow_fltbms : 49|1@1+ (1,0) [0|1] "Status"  VIU
 SG_ chg_hb_fltbms : 50|1@1+ (1,0) [0|1] "Status"  VIU
 SG_ hvil_fltbms : 51|1@1+ (1,0) [0|1] "Status"  VIU
 SG_ dsgoff_rel_fltbms : 52|1@1+ (1,0) [0|1] "Status"  VIU
 SG_ hazard_fltbms : 53|1@1+ (1,0) [0|1] "Status"  VIU
 SG_ hw_scd_fltbms : 54|1@1+ (1,0) [0|1] "Status"  VIU
 SG_ sysfail_fltbms : 55|1@1+ (1,0) [0|1] "Status"  VIU
 SG_ other_i2c_fail_fltbms : 56|1@1+ (1,0) [0|1] "Status"  VIU
 SG_ aps_oc_lat_fltbms : 57|1@1+ (1,0) [0|1] "Status"  VIU
 SG_ aps_oc_permlat_fltbms : 58|1@1+ (1,0) [0|1] "Status"  VIU
 SG_ ext_opdis_fltbms : 59|1@1+ (1,0) [0|1] "Status"  VIU
 SG_ false_chgr_fltbms : 60|1@1+ (1,0) [0|1] "Status"  VIU
 SG_ occ1_fltbms : 61|1@1+ (1,0) [0|1] "Status"  VIU
 SG_ occ2_fltbms : 62|1@1+ (1,0) [0|1] "Status"  VIU
 SG_ occ3_fltbms : 63|1@1+ (1,0) [0|1] "Status"  VIU

BO_ 1823 DBGbms_CsFlowRate_MSG30: 8 BMS
 SG_ perphcan_tx_errcnt : 0|8@1+ (1,0) [0|255] "x"  VIU
 SG_ perphcan_rx_errcnt : 8|7@1+ (1,0) [0|127] "x"  VIU
 SG_ perphcan_errpass : 15|1@1+ (1,0) [0|1] "x"  VIU
 SG_ LowHost_SOH : 16|8@1+ (1,0) [0|255] "percent"  VIU
 SG_ UppHost_SOH : 24|8@1+ (1,0) [0|255] "percent"  VIU
 SG_ Ext_Avg_Vtg_LowHost : 32|16@1+ (1,0) [0|65535] "mV"  VIU
 SG_ Ext_Avg_Vtg_UppHost : 48|16@1+ (1,0) [0|65535] "mV"  VIU

BO_ 1840 DBGbms_RawAFE1_MSG41: 8 BMS
 SG_ AFE1_t1_adc_cnt : 0|16@1+ (1,0) [0|65535] "W"  VIU
 SG_ AFE1_t2_adc_cnt : 16|16@1+ (1,0) [0|65535] "W"  VIU
 SG_ AFE1_t3_adc_cnt : 32|16@1+ (1,0) [0|65535] "W"  VIU
 SG_ AFE1_gt_adc_cnt : 48|16@1+ (1,0) [0|65535] "W"  VIU

BO_ 1841 DBGbms_RawAdc1_MSG42: 8 BMS
 SG_ NTC1_adc_cnt : 0|16@1+ (1,0) [0|65535] "W"  VIU
 SG_ NTC2_adc_cnt : 16|16@1+ (1,0) [0|65535] "W"  VIU
 SG_ NTC3_adc_cnt : 32|16@1+ (1,0) [0|65535] "W"  VIU
 SG_ NTC4_adc_cnt : 48|16@1+ (1,0) [0|65535] "W"  VIU

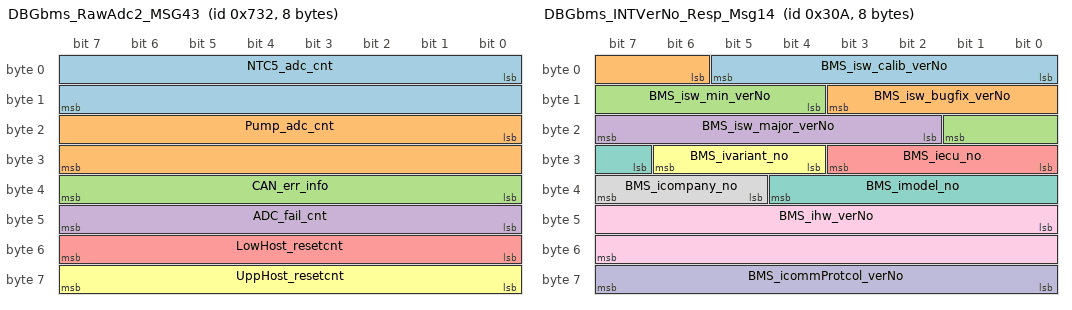
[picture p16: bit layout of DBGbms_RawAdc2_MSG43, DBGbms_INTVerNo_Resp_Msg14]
BO_ 1842 DBGbms_RawAdc2_MSG43: 8 BMS
 SG_ NTC5_adc_cnt : 0|16@1+ (1,0) [0|65535] "W"  VIU
 SG_ Pump_adc_cnt : 16|16@1+ (1,0) [0|65535] "W"  VIU
 SG_ CAN_err_info : 32|8@1+ (1,0) [0|255] "x"  VIU
 SG_ ADC_fail_cnt : 40|8@1+ (1,0) [0|255] "x"  VIU
 SG_ LowHost_resetcnt : 48|8@1+ (1,0) [0|255] "x"  VIU
 SG_ UppHost_resetcnt : 56|8@1+ (1,0) [0|255] "x"  VIU

BO_ 1843 DBGbms_RawCSAdc_MSG44: 8 BMS
 SG_ CS1_adc_cnt : 0|16@1+ (1,0) [0|65535] "W"  VIU
 SG_ CS2_adc_cnt : 16|16@1+ (1,0) [0|65535] "W"  VIU
 SG_ CS3_adc_cnt : 32|16@1+ (1,0) [0|65535] "W"  VIU
 SG_ CS4_adc_cnt : 48|16@1+ (1,0) [0|65535] "W"  VIU

BO_ 1844 DBGbms_RawAFE2_MSG45: 8 BMS
 SG_ AFE2_t1_adc_cnt : 0|16@1+ (1,0) [0|65535] "W"  VIU
 SG_ AFE2_t2_adc_cnt : 16|16@1+ (1,0) [0|65535] "W"  VIU
 SG_ AFE2_t3_adc_cnt : 32|16@1+ (1,0) [0|65535] "W"  VIU
 SG_ AFE2_gt_adc_cnt : 48|16@1+ (1,0) [0|65535] "W"  VIU

BO_ 1845 DBGbms_OpnCT_Fcnt3_MSG46: 8 BMS
 SG_ open_ct1_flg : 0|1@1+ (1,0) [0|1] "x"  VIU
 SG_ open_ct2_flg : 1|1@1+ (1,0) [0|1] "x"  VIU
 SG_ open_ct3_flg : 2|1@1+ (1,0) [0|1] "x"  VIU
 SG_ open_ct4_flg : 3|1@1+ (1,0) [0|1] "x"  VIU
 SG_ open_ct5_flg : 4|1@1+ (1,0) [0|1] "x"  VIU
 SG_ open_ct6_flg : 5|1@1+ (1,0) [0|1] "x"  VIU
 SG_ open_ct7_flg : 6|1@1+ (1,0) [0|1] "x"  VIU
 SG_ open_ct8_flg : 7|1@1+ (1,0) [0|1] "x"  VIU
 SG_ open_ct9_flg : 8|1@1+ (1,0) [0|1] "x"  VIU
 SG_ open_ct10_flg : 9|1@1+ (1,0) [0|1] "x"  VIU
 SG_ open_ct11_flg : 10|1@1+ (1,0) [0|1] "x"  VIU
 SG_ open_ct12_flg : 11|1@1+ (1,0) [0|1] "x"  VIU
 SG_ imd_coff_flt_cnt : 16|16@1+ (1,0) [0|65535] "x"  VIU
 SG_ Hvil_debug_param2 : 32|8@1+ (1,0) [0|255] "x"  VIU
 SG_ Hvil_debug_param3 : 40|8@1+ (1,0) [0|255] "x"  VIU
 SG_ Hvil_debug_param4 : 48|8@1+ (1,0) [0|255] "x"  VIU
 SG_ canrx_veh_mode : 56|4@1+ (1,0) [0|15] "x"  VIU
 SG_ pack_bal_meas_b : 60|1@1+ (1,0) [0|1] "x"  VIU
 SG_ pack_bal_en_b : 61|1@1+ (1,0) [0|1] "x"  VIU
 SG_ afecfg_reset_state : 62|2@1+ (1,0) [0|3] "x"  VIU

BO_ 1846 DBGbms_Fltcnt2_MSG48: 8 BMS
 SG_ hvil_det_flt_cnt : 0|16@1+ (1,0) [0|65535] "x"  VIU
 SG_ hvil_coff_flt_cnt : 16|16@1+ (1,0) [0|65535] "x"  VIU
 SG_ LAFE_p1_rdsts : 32|2@1+ (1,0) [0|3] "x"  VIU
 SG_ LAFE_p2_rdsts : 34|2@1+ (1,0) [0|3] "x"  VIU
 SG_ LAFE_p3_rdsts : 36|2@1+ (1,0) [0|3] "x"  VIU
 SG_ LAFE_p4_rdsts : 38|2@1+ (1,0) [0|3] "x"  VIU
 SG_ LAFE_p5_rdsts : 40|2@1+ (1,0) [0|3] "x"  VIU
 SG_ LAFE_p1_wrsts : 42|1@1+ (1,0) [0|1] "x"  VIU
 SG_ LAFE_p2_wrsts : 43|1@1+ (1,0) [0|1] "x"  VIU
 SG_ LAFE_p3_wrsts : 44|1@1+ (1,0) [0|1] "x"  VIU
 SG_ LAFE_p4_wrsts : 45|1@1+ (1,0) [0|1] "x"  VIU
 SG_ LAFE_p5_wrsts : 46|1@1+ (1,0) [0|1] "x"  VIU
 SG_ reserved_b10 : 47|1@1+ (1,0) [0|1] "x"  VIU
 SG_ UAFE_p1_rdsts : 48|2@1+ (1,0) [0|3] "x"  VIU
 SG_ UAFE_p2_rdsts : 50|2@1+ (1,0) [0|3] "x"  VIU
 SG_ UAFE_p3_rdsts : 52|2@1+ (1,0) [0|3] "x"  VIU
 SG_ UAFE_p4_rdsts : 54|2@1+ (1,0) [0|3] "x"  VIU
 SG_ UAFE_p5_rdsts : 56|2@1+ (1,0) [0|3] "x"  VIU
 SG_ UAFE_p1_wrsts : 58|1@1+ (1,0) [0|1] "x"  VIU
 SG_ UAFE_p2_wrsts : 59|1@1+ (1,0) [0|1] "x"  VIU
 SG_ UAFE_p3_wrsts : 60|1@1+ (1,0) [0|1] "x"  VIU
 SG_ UAFE_p4_wrsts : 61|1@1+ (1,0) [0|1] "x"  VIU
 SG_ UAFE_p5_wrsts : 62|1@1+ (1,0) [0|1] "x"  VIU
 SG_ reserved_b11 : 63|1@1+ (1,0) [0|1] "x"  VIU

BO_ 1847 DBGbms_FltCnt1_MSG49: 8 BMS
 SG_ hvil_flt_cnt : 0|32@1+ (1,0) [0|4294967295] "x"  VIU
 SG_ imd_flt_cnt : 32|32@1+ (1,0) [0|4294967295] "x"  VIU

BO_ 778 DBGbms_INTVerNo_Resp_Msg14: 8 BMS
 SG_ BMS_isw_calib_verNo : 0|6@1+ (1,0) [0|63] ""  VIU
 SG_ BMS_isw_bugfix_verNo : 6|6@1+ (1,0) [0|63] ""  VIU
 SG_ BMS_isw_min_verNo : 12|6@1+ (1,0) [0|63] ""  VIU
 SG_ BMS_isw_major_verNo : 18|6@1+ (1,0) [0|63] ""  VIU
 SG_ BMS_iecu_no : 24|4@1+ (1,0) [0|15] ""  VIU
 SG_ BMS_ivariant_no : 28|3@1+ (1,0) [0|7] ""  VIU
 SG_ BMS_imodel_no : 31|6@1+ (1,0) [0|63] ""  VIU
 SG_ BMS_icompany_no : 37|3@1+ (1,0) [0|7] ""  VIU
 SG_ BMS_ihw_verNo : 40|16@1+ (1,0) [0|65535] ""  VIU
 SG_ BMS_icommProtcol_verNo : 56|8@1+ (1,0) [0|255] ""  VIU

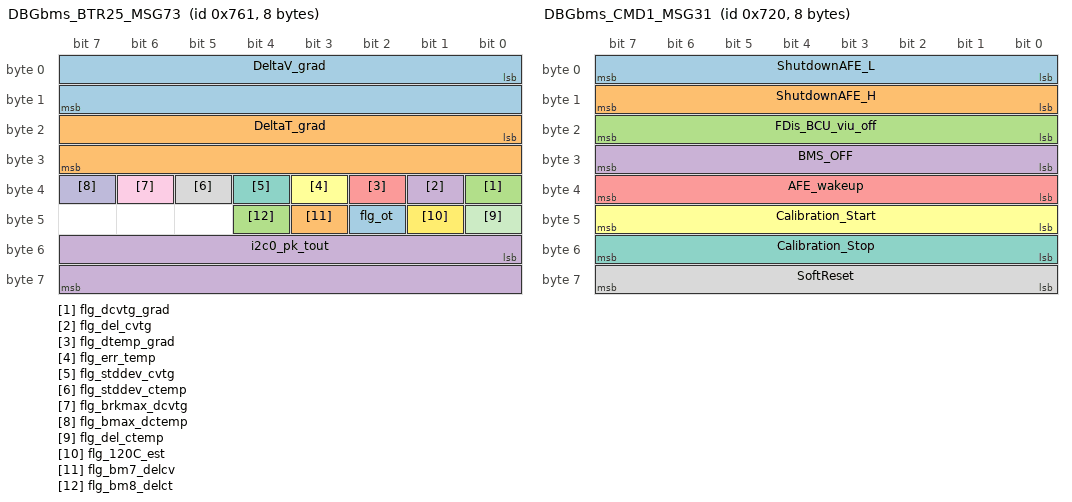
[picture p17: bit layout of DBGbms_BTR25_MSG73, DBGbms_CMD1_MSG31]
BO_ 1889 DBGbms_BTR25_MSG73: 8 BMS
 SG_ DeltaV_grad : 0|16@1+ (1,0) [0|65535] "mV"  VIU
 SG_ DeltaT_grad : 16|16@1+ (1,0) [0|65535] "mV"  VIU
 SG_ flg_dcvtg_grad : 32|1@1+ (1,0) [0|1] "x"  VIU
 SG_ flg_del_cvtg : 33|1@1+ (1,0) [0|1] "x"  VIU
 SG_ flg_dtemp_grad : 34|1@1+ (1,0) [0|1] "x"  VIU
 SG_ flg_err_temp : 35|1@1+ (1,0) [0|1] "x"  VIU
 SG_ flg_stddev_cvtg : 36|1@1+ (1,0) [0|1] "x"  VIU
 SG_ flg_stddev_ctemp : 37|1@1+ (1,0) [0|1] "x"  VIU
 SG_ flg_brkmax_dcvtg : 38|1@1+ (1,0) [0|1] "x"  VIU
 SG_ flg_bmax_dctemp : 39|1@1+ (1,0) [0|1] "x"  VIU
 SG_ flg_del_ctemp : 40|1@1+ (1,0) [0|1] "x"  VIU
 SG_ flg_120C_est : 41|1@1+ (1,0) [0|1] "x"  VIU
 SG_ flg_ot : 42|1@1+ (1,0) [0|1] "x"  VIU
 SG_ flg_bm7_delcv : 43|1@1+ (1,0) [0|1] "x"  VIU
 SG_ flg_bm8_delct : 44|1@1+ (1,0) [0|1] "x"  VIU
 SG_ i2c0_pk_tout : 48|16@1+ (1,0) [0|65535] "x"  VIU

BO_ 1824 DBGbms_CMD1_MSG31: 8 VIU
 SG_ ShutdownAFE_L : 0|8@1+ (1,0) [0|255] "Binary Data (0 or 1)"  BCU,BMS
 SG_ ShutdownAFE_H : 8|8@1+ (1,0) [0|255] "Binary Data (0 or 1)"  BCU,BMS
 SG_ FDis_BCU_viu_off : 16|8@1+ (1,0) [0|255] "Binary Data (0 or 1)"  BCU,BMS
 SG_ BMS_OFF : 24|8@1+ (1,0) [0|255] "Binary Data (0 or 1)"  BCU,BMS
 SG_ AFE_wakeup : 32|8@1+ (1,0) [0|255] "Binary Data (0 or 1)"  BCU,BMS
 SG_ Calibration_Start : 40|8@1+ (1,0) [0|255] "Binary Data (0 or 1)"  BCU,BMS
 SG_ Calibration_Stop : 48|8@1+ (1,0) [0|255] "Binary Data (0 or 1)"  BCU,BMS
 SG_ SoftReset : 56|8@1+ (1,0) [0|255] "Binary Data (0 or 1)"  BCU,BMS

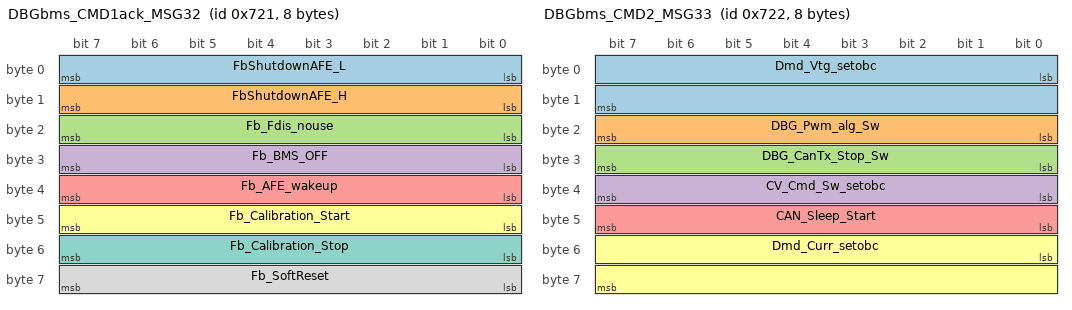
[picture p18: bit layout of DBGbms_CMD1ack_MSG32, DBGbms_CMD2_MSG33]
BO_ 1825 DBGbms_CMD1ack_MSG32: 8 BMS
 SG_ FbShutdownAFE_L : 0|8@1+ (1,0) [0|255] "Binary Data (0 or 1)"  VIU
 SG_ FbShutdownAFE_H : 8|8@1+ (1,0) [0|255] "Binary Data (0 or 1)"  VIU
 SG_ Fb_Fdis_nouse : 16|8@1+ (1,0) [0|255] "Binary Data (0 or 1)"  VIU
 SG_ Fb_BMS_OFF : 24|8@1+ (1,0) [0|255] "Binary Data (0 or 1)"  VIU
 SG_ Fb_AFE_wakeup : 32|8@1+ (1,0) [0|255] "Binary Data (0 or 1)"  VIU
 SG_ Fb_Calibration_Start : 40|8@1+ (1,0) [0|255] "Binary Data (0 or 1)"  VIU
 SG_ Fb_Calibration_Stop : 48|8@1+ (1,0) [0|255] "Binary Data (0 or 1)"  VIU
 SG_ Fb_SoftReset : 56|8@1+ (1,0) [0|255] "Binary Data (0 or 1)"  VIU

BO_ 1826 DBGbms_CMD2_MSG33: 8 VIU
 SG_ Dmd_Vtg_setobc : 0|16@1+ (0.1,0) [0|65535] "V"  BMS
 SG_ DBG_Pwm_alg_Sw : 16|8@1+ (1,0) [0|255] "Binary Data (0 or 1)"  BMS
 SG_ DBG_CanTx_Stop_Sw : 24|8@1+ (1,0) [0|255] "Binary Data (0 or 1)"  BMS
 SG_ CV_Cmd_Sw_setobc : 32|8@1+ (1,0) [0|255] "Binary Data (0 or 1)"  BMS
 SG_ CAN_Sleep_Start : 40|8@1+ (1,0) [0|255] "Binary Data (0 or 1)"  BMS
 SG_ Dmd_Curr_setobc : 48|16@1+ (0.01,0) [0|65535] "A"  BMS

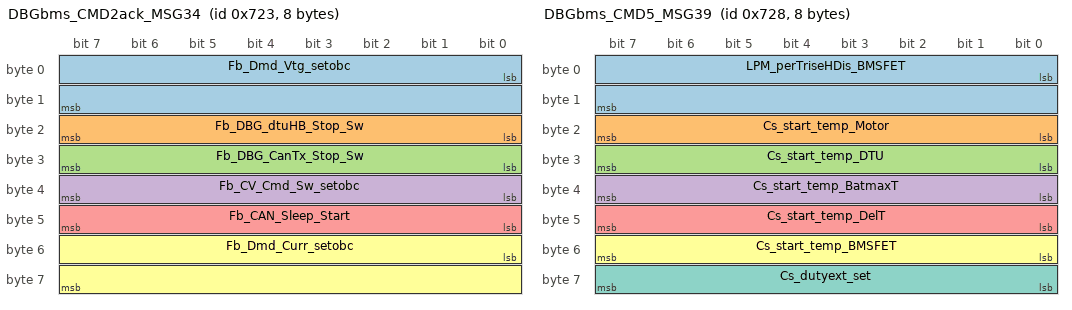
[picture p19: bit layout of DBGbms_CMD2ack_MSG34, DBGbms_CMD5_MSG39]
BO_ 1827 DBGbms_CMD2ack_MSG34: 8 BMS
 SG_ Fb_Dmd_Vtg_setobc : 0|16@1+ (0.1,0) [0|65535] "V"  VIU
 SG_ Fb_DBG_dtuHB_Stop_Sw : 16|8@1+ (1,0) [0|255] "Binary Data (0 or 1)"  VIU
 SG_ Fb_DBG_CanTx_Stop_Sw : 24|8@1+ (1,0) [0|255] "Binary Data (0 or 1)"  VIU
 SG_ Fb_CV_Cmd_Sw_setobc : 32|8@1+ (1,0) [0|255] "Binary Data (0 or 1)"  VIU
 SG_ Fb_CAN_Sleep_Start : 40|8@1+ (1,0) [0|255] "Binary Data (0 or 1)"  VIU
 SG_ Fb_Dmd_Curr_setobc : 48|16@1+ (0.01,0) [0|65535] "A"  VIU

BO_ 1828 DBGbms_CMD3_MSG35: 8 VIU
 SG_ Sleep_Wake_Trig : 0|8@1+ (1,0) [0|255] "Binary Data"  BMS

BO_ 1829 DBGbms_CMD3ack_MSG36: 8 BMS
 SG_ Fb_Sleep_Wake_Trig : 0|8@1+ (1,0) [0|255] "Binary Data"  VIU

BO_ 1830 DBGbms_CMD4_MSG37: 8 VIU
 SG_ LPM_perTriseHDis_Motor : 0|16@1+ (0.0001,0) [0|65535] "LPM"  BMS
 SG_ LPM_perTriseHDis_DTU : 16|16@1+ (0.0001,0) [0|65535] "LPM"  BMS
 SG_ LPM_perTriseHDis_BatmaxT : 32|16@1+ (0.0001,0) [0|65535] "LPM"  BMS
 SG_ LPM_perTriseHDis_DelT : 48|16@1+ (0.0001,0) [0|65535] "LPM"  BMS

BO_ 1831 DBGbms_CMD4ack_MSG38: 8 BMS
 SG_ FbLPM_perTriseHDis_Motor : 0|16@1+ (0.0001,0) [0|65535] "LPM"  VIU
 SG_ FbLPM_perTriseHDis_DTU : 16|16@1+ (0.0001,0) [0|65535] "LPM"  VIU
 SG_ FbLPM_perTriseHDis_BatmaxT : 32|16@1+ (0.0001,0) [0|65535] "LPM"  VIU
 SG_ FbLPM_perTriseHDis_DelT : 48|16@1+ (0.0001,0) [0|65535] "LPM"  VIU

BO_ 1832 DBGbms_CMD5_MSG39: 8 VIU
 SG_ LPM_perTriseHDis_BMSFET : 0|16@1+ (0.0001,0) [0|65535] "LPM"  BMS
 SG_ Cs_start_temp_Motor : 16|8@1+ (1,0) [0|255] "degC"  BMS
 SG_ Cs_start_temp_DTU : 24|8@1+ (1,0) [0|255] "degC"  BMS
 SG_ Cs_start_temp_BatmaxT : 32|8@1+ (1,0) [0|255] "degC"  BMS
 SG_ Cs_start_temp_DelT : 40|8@1+ (1,0) [0|255] "degC"  BMS
 SG_ Cs_start_temp_BMSFET : 48|8@1+ (1,0) [0|255] "degC"  BMS
 SG_ Cs_dutyext_set : 56|8@1+ (1,0) [0|255] "degC"  BMS

BO_ 1833 DBGbms_CMD5ack_MSG40: 8 BMS
 SG_ FbLPM_perTriseHDis_BMSFET : 0|16@1+ (0.0001,0) [0|65535] "LPM"  VIU

VAL_ 773 BMS_state 0 "NA" 1 "DEAD" 2 "INIT" 3 "PCHG" 4 "CHG_TRICKLE" 5 "CHG_UV" 6 "CHG_NORMAL" 7 "DSG_NORMAL" 8 "DSG_NOCHG" 9 "DSG_LIMP" 10 "BOOT" 11 "SLEEP_UV" 12 "SLEEP_DPDSG" 13 "RESERVED" 14 "FAULT_CRITICAL" 15 "VACATION" 16 "DIAGNOSTIC" ;
VAL_ 773 BMS_scd_fb_status 0 "NOT_ACT" 1 "ACTIVE" ;
VAL_ 773 BMS_charger_detect_status 0 "NOT_ACT" 1 "ACTIVE" ;
VAL_ 773 BMS_fet_state 0 "ALL_MFET_OFF" 1 "PCHG_MFET_ONLY_ON" 2 "CHG_MFET_ONLY_ON" 3 "CHG_PCHG_MFET_ON" 4 "DSG_MFET_ONLY_ON" 5 "DSG_PCHG_MFET_ON" 6 "BOTH_MAIN_MFET_ON" 7 "ALL_MFET_ON" ;
VAL_ 773 BMS_chg_mcu_status 0 "NOT_ACT" 1 "ACTIVE" ;
VAL_ 773 BMS_dchg_mcu_status 0 "NOT_ACT" 1 "ACTIVE" ;
VAL_ 773 BMS_dchg_fb_status 0 "NOT_ACT" 1 "ACTIVE" ;
VAL_ 773 BMS_calib_start_status 0 "NOT_ACT" 1 "ACTIVE" ;
VAL_ 773 BMS_sop_derating_flag 0 "NOT_ACT" 1 "ACTIVE" ;
VAL_ 773 BMS_charger_plugged_status 0 "NOT_ACT" 1 "ACTIVE" ;
VAL_ 773 BMS_cstemp_warn_status 0 "NOT_ACT" 1 "ACTIVE" ;
VAL_ 773 BMS_regen_disable_flag 0 "NOT_ACT" 1 "ACTIVE" ;
VAL_ 773 BMS_diagchk_BattStatus 0 "DefaultNA" 1 "GREEN" 2 "ORANGE" 3 "RED" ;
VAL_ 773 BMS_diagchk_BattTemp 0 "DefaultNA" 1 "GREEN" 2 "ORANGE" 3 "RED" ;
VAL_ 773 BMS_diagchk_BattVtg 0 "DefaultNA" 1 "GREEN" 2 "ORANGE" 3 "RED" ;
VAL_ 773 BMS_diagchk_CoolantTemp 0 "DefaultNA" 1 "GREEN" 2 "ORANGE" 3 "RED" ;
VAL_ 773 BMS_can_state 0 "WAKEUP" 1 "NORMAL" 2 "LIMITED" 3 "FAIL" ;
VAL_ 773 BMS_chgr_full_status 0 "NOT_ACT" 1 "ACTIVE" ;
VAL_ 773 BMS_fchgr_pres_status 0 "NOT_ACT" 1 "ACTIVE" ;
VAL_ 773 BMS_chgr_fault_status 0 "NOT_ACT" 1 "ACTIVE" ;
VAL_ 512 BMS_afe_cov_fault 0 "NOT_ACT" 1 "ACTIVE" ;
VAL_ 512 BMS_afe_cuv_fault 0 "NOT_ACT" 1 "ACTIVE" ;
VAL_ 512 BMS_afe_cot_chg_fault 0 "NOT_ACT" 1 "ACTIVE" ;
VAL_ 512 BMS_afe_cot_dchg_fault 0 "NOT_ACT" 1 "ACTIVE" ;
VAL_ 512 BMS_afe_cut_chg_fault 0 "NOT_ACT" 1 "ACTIVE" ;
VAL_ 512 BMS_afe_cut_dchg_fault 0 "NOT_ACT" 1 "ACTIVE" ;
VAL_ 512 BMS_afe_oc_chg_fault 0 "NOT_ACT" 1 "ACTIVE" ;
VAL_ 512 BMS_afe_oc_dchg_fault 0 "NOT_ACT" 1 "ACTIVE" ;
VAL_ 512 BMS_afe_sc_detetction_fault 0 "NOT_ACT" 1 "ACTIVE" ;
VAL_ 512 BMS_afe_overload_detect_fault 0 "NOT_ACT" 1 "ACTIVE" ;
VAL_ 512 BMS_afe_fet_off_fault 0 "NOT_ACT" 1 "ACTIVE" ;
VAL_ 512 BMS_afe_oc_fault 0 "NOT_ACT" 1 "ACTIVE" ;
VAL_ 512 BMS_afe_otf_fault 0 "NOT_ACT" 1 "ACTIVE" ;
VAL_ 512 BMS_chgfetoff_fault 0 "NOT_ACT" 1 "ACTIVE" ;
VAL_ 512 BMS_cov_fault 0 "NOT_ACT" 1 "ACTIVE" ;
VAL_ 512 BMS_cuv_fault 0 "NOT_ACT" 1 "ACTIVE" ;
VAL_ 512 BMS_ddsg_fault 0 "NOT_ACT" 1 "ACTIVE" ;
VAL_ 512 BMS_del_cv_fault 0 "NOT_ACT" 1 "ACTIVE" ;
VAL_ 512 BMS_pchg_tout_fault 0 "NOT_ACT" 1 "ACTIVE" ;
VAL_ 512 BMS_del_ct_fault 0 "NOT_ACT" 1 "ACTIVE" ;
VAL_ 512 BMS_hostl_i2c_fault 0 "NOT_ACT" 1 "ACTIVE" ;
VAL_ 512 BMS_hostu_i2c_fault 0 "NOT_ACT" 1 "ACTIVE" ;
VAL_ 512 BMS_cot_chg_fault 0 "NOT_ACT" 1 "ACTIVE" ;
VAL_ 512 BMS_cot_dsg_fault 0 "NOT_ACT" 1 "ACTIVE" ;
VAL_ 512 BMS_cut_chg_fault 0 "NOT_ACT" 1 "ACTIVE" ;
VAL_ 512 BMS_cut_dsg_fault 0 "NOT_ACT" 1 "ACTIVE" ;
VAL_ 512 BMS_fot_fault 0 "NOT_ACT" 1 "ACTIVE" ;
VAL_ 512 BMS_csot_fault 0 "NOT_ACT" 1 "ACTIVE" ;
VAL_ 512 BMS_afedieot_fault 0 "NOT_ACT" 1 "ACTIVE" ;
VAL_ 512 BMS_imd_fault 0 "NOT_ACT" 1 "ACTIVE" ;
VAL_ 512 BMS_cvow_fault 0 "NOT_ACT" 1 "ACTIVE" ;
VAL_ 512 BMS_ctow_fault 0 "NOT_ACT" 1 "ACTIVE" ;
VAL_ 512 BMS_nctow_fault 0 "NOT_ACT" 1 "ACTIVE" ;
VAL_ 512 BMS_cs_ic_fail_fault 0 "NOT_ACT" 1 "ACTIVE" ;
VAL_ 512 BMS_imd_ic_fail_fault 0 "NOT_ACT" 1 "ACTIVE" ;
VAL_ 512 BMS_ftow_fault 0 "NOT_ACT" 1 "ACTIVE" ;
VAL_ 512 BMS_cstow_fault 0 "NOT_ACT" 1 "ACTIVE" ;
VAL_ 512 BMS_aps_scd_fault 0 "NOT_ACT" 1 "ACTIVE" ;
VAL_ 512 BMS_aps_ot_fault 0 "NOT_ACT" 1 "ACTIVE" ;
VAL_ 512 BMS_aps_ov_fault 0 "NOT_ACT" 1 "ACTIVE" ;
VAL_ 512 BMS_aps_oc_fault 0 "NOT_ACT" 1 "ACTIVE" ;
VAL_ 512 BMS_fetchg_short_fault 0 "NOT_ACT" 1 "ACTIVE" ;
VAL_ 512 BMS_fetdsg_short_fault 0 "NOT_ACT" 1 "ACTIVE" ;
VAL_ 512 BMS_pchg_pk_fault 0 "NOT_ACT" 1 "ACTIVE" ;
VAL_ 512 BMS_crit_rel_fault 0 "NOT_ACT" 1 "ACTIVE" ;
VAL_ 512 BMS_pchg_rot_fault 0 "NOT_ACT" 1 "ACTIVE" ;
VAL_ 512 BMS_pchg_rtow_fault 0 "NOT_ACT" 1 "ACTIVE" ;
VAL_ 512 BMS_chg_hb_fault 0 "NOT_ACT" 1 "ACTIVE" ;
VAL_ 512 BMS_hvil_fault 0 "NOT_ACT" 1 "ACTIVE" ;
VAL_ 512 BMS_dsgoff_rel_fault 0 "NOT_ACT" 1 "ACTIVE" ;
VAL_ 512 BMS_hazard_fault 0 "NOT_ACT" 1 "ACTIVE" ;
VAL_ 512 BMS_hw_scd_fault 0 "NOT_ACT" 1 "ACTIVE" ;
VAL_ 512 BMS_sysfail_fault 0 "NOT_ACT" 1 "ACTIVE" ;
VAL_ 512 BMS_other_i2c_fault 0 "NOT_ACT" 1 "ACTIVE" ;
VAL_ 512 BMS_aps_oclat_fault 0 "NOT_ACT" 1 "ACTIVE" ;
VAL_ 512 BMS_aps_oclat_permfault 0 "NOT_ACT" 1 "ACTIVE" ;
VAL_ 512 BMS_ext_opdis_fault 0 "NOT_ACT" 1 "ACTIVE" ;
VAL_ 512 BMS_false_chgr_fault 0 "NOT_ACT" 1 "ACTIVE" ;
VAL_ 512 BMS_occ1_fault 0 "NOT_ACT" 1 "ACTIVE" ;
VAL_ 512 BMS_occ2_fault 0 "NOT_ACT" 1 "ACTIVE" ;
VAL_ 512 BMS_occ3_fault 0 "NOT_ACT" 1 "ACTIVE" ;
VAL_ 513 BMS_bat_cov_warning 0 "NOT_ACT" 1 "ACTIVE" ;
VAL_ 513 BMS_bat_cuv_warning 0 "NOT_ACT" 1 "ACTIVE" ;
VAL_ 513 BMS_bat_del_v_warning 0 "NOT_ACT" 1 "ACTIVE" ;
VAL_ 513 BMS_bat_cot_warning 0 "NOT_ACT" 1 "ACTIVE" ;
VAL_ 513 BMS_bat_cut_warning 0 "NOT_ACT" 1 "ACTIVE" ;
VAL_ 513 BMS_bat_del_ct_warning 0 "NOT_ACT" 1 "ACTIVE" ;
VAL_ 513 BMS_bat_fot_warning 0 "NOT_ACT" 1 "ACTIVE" ;
VAL_ 513 BMS_bat_csot_warning 0 "NOT_ACT" 1 "ACTIVE" ;
VAL_ 513 BMS_bat_afedieot_warning 0 "NOT_ACT" 1 "ACTIVE" ;
VAL_ 513 BMS_bat_occ_warning 0 "NOT_ACT" 1 "ACTIVE" ;
VAL_ 513 BMS_bat_ocd_warning 0 "NOT_ACT" 1 "ACTIVE" ;
VAL_ 513 BMS_bat_pusoc_warning 0 "NOT_ACT" 1 "ACTIVE" ;
VAL_ 513 BMS_hvil_warning 0 "NOT_ACT" 1 "ACTIVE" ;
VAL_ 513 BMS_bat_imd_warning 0 "NOT_ACT" 1 "ACTIVE" ;
VAL_ 513 BMS_batcrit_lvl1_warning 0 "NOT_ACT" 1 "ACTIVE" ;
VAL_ 513 BMS_batcrit_lvl2_warning 0 "NOT_ACT" 1 "ACTIVE" ;
VAL_ 513 BMS_hostl_i2c_warning 0 "NOT_ACT" 1 "ACTIVE" ;
VAL_ 513 BMS_hostu_i2c_warning 0 "NOT_ACT" 1 "ACTIVE" ;
VAL_ 513 BMS_pump_oload_warning 0 "NOT_ACT" 1 "ACTIVE" ;
VAL_ 513 BMS_dpdsg_warning 0 "NOT_ACT" 1 "ACTIVE" ;
VAL_ 513 BMS_cotc_warning 0 "NOT_ACT" 1 "ACTIVE" ;
VAL_ 513 BMS_cutc_warning 0 "NOT_ACT" 1 "ACTIVE" ;
VAL_ 793 BMS_Fullchg_Status 0 "NOT_ACT" 1 "ACTIVE" ;
VAL_ 793 BMS_ChargMode_Status 0 "NOT_ACT" 1 "ACTIVE" ;
VAL_ 793 BMS_Charger_Conn_Status 0 "NOT_ACT" 1 "ACTIVE" ;
VAL_ 793 BMS_Charger_Start_stp_Cmd 0 "Stop" 1 "Start" ;
VAL_ 793 BMS_CV_Mode_Sw_Cmd 0 "CC" 1 "CV" ;
VAL_ 794 BMS_code_m25 0 "BMS" 1 "BCU" 2 "DTU" 3 "OBC" ;
VAL_ 806 BMS_ecu_no 3 "BMS" ;
VAL_ 1806 BMSstate 0 "NA" 1 "DEAD" 2 "INIT" 3 "PCHG" 4 "CHG_TRICKLE" 5 "CHG_UV" 6 "CHG_NORMAL" 7 "DSG_NORMAL" 8 "DSG_NOCHG" 9 "DSG_LIMP" 10 "BOOT" 11 "SLEEP_UV" 12 "SLEEP_DPDSG" 13 "RESVD" 14 "FAULT_CRITICAL" 15 "VACATION" 16 "DIAGNOSTIC" ;
VAL_ 1806 FET_State_pchg 0 "OFF" 1 "ON" ;
VAL_ 1806 FET_State_chg 0 "OFF" 1 "ON" ;
VAL_ 1806 FET_State_dsg 0 "OFF" 1 "ON" ;
VAL_ 1806 PumpSysState 0 "NA" 1 "NORMAL" 2 "NOLOAD" 3 "OLOAD" ;
VAL_ 1807 CC_CV_state 0 "NORMAL_CC" 1 "FIRST_CV" 2 "SECOND_CC" 3 "FINAL_CV" 4 "FULLCHG" ;
VAL_ 1821 cov_warnbms 0 "NOT_ACT" 1 "ACTIVE" ;
VAL_ 1821 cuv_warnbms 0 "NOT_ACT" 1 "ACTIVE" ;
VAL_ 1821 del_v_warnbms 0 "NOT_ACT" 1 "ACTIVE" ;
VAL_ 1821 cotd_warnbms 0 "NOT_ACT" 1 "ACTIVE" ;
VAL_ 1821 cutd_warnbms 0 "NOT_ACT" 1 "ACTIVE" ;
VAL_ 1821 del_ct_warnbms 0 "NOT_ACT" 1 "ACTIVE" ;
VAL_ 1821 fot_warnbms 0 "NOT_ACT" 1 "ACTIVE" ;
VAL_ 1821 csot_warnbms 0 "NOT_ACT" 1 "ACTIVE" ;
VAL_ 1821 afedieot_warnbms 0 "NOT_ACT" 1 "ACTIVE" ;
VAL_ 1821 occ_warnbms 0 "NOT_ACT" 1 "ACTIVE" ;
VAL_ 1821 ocd_warnbms 0 "NOT_ACT" 1 "ACTIVE" ;
VAL_ 1821 pusoc_warnbms 0 "NOT_ACT" 1 "ACTIVE" ;
VAL_ 1821 hvil_warnbms 0 "NOT_ACT" 1 "ACTIVE" ;
VAL_ 1821 imd_warnbms 0 "NOT_ACT" 1 "ACTIVE" ;
VAL_ 1821 crit_lvl1_warnbms 0 "NOT_ACT" 1 "ACTIVE" ;
VAL_ 1821 crit_lvl2_warnbms 0 "NOT_ACT" 1 "ACTIVE" ;
VAL_ 1821 hostl_i2c_warnbms 0 "NOT_ACT" 1 "ACTIVE" ;
VAL_ 1821 hostu_i2c_warnbms 0 "NOT_ACT" 1 "ACTIVE" ;
VAL_ 1821 pump_oload_warnbms 0 "NOT_ACT" 1 "ACTIVE" ;
VAL_ 1821 dpdsg_warnbms 0 "NOT_ACT" 1 "ACTIVE" ;
VAL_ 1821 cotc_warnbms 0 "NOT_ACT" 1 "ACTIVE" ;
VAL_ 1821 cutc_warnbms 0 "NOT_ACT" 1 "ACTIVE" ;
VAL_ 1822 afe_cov_fltbms 0 "NOT_ACT" 1 "ACTIVE" ;
VAL_ 1822 afe_cuv_fltbms 0 "NOT_ACT" 1 "ACTIVE" ;
VAL_ 1822 afe_cot_chg_fltbms 0 "NOT_ACT" 1 "ACTIVE" ;
VAL_ 1822 afe_cot_dchg_fltbms 0 "NOT_ACT" 1 "ACTIVE" ;
VAL_ 1822 afe_cut_chg_fltbms 0 "NOT_ACT" 1 "ACTIVE" ;
VAL_ 1822 afe_cut_dchg_fltbms 0 "NOT_ACT" 1 "ACTIVE" ;
VAL_ 1822 afe_oc_chg_fltbms 0 "NOT_ACT" 1 "ACTIVE" ;
VAL_ 1822 afe_oc_dchg_fltbms 0 "NOT_ACT" 1 "ACTIVE" ;
VAL_ 1822 afe_sc_detect_fltbms 0 "NOT_ACT" 1 "ACTIVE" ;
VAL_ 1822 afe_oload_detect_fltbms 0 "NOT_ACT" 1 "ACTIVE" ;
VAL_ 1822 afe_fet_off_fltbms 0 "NOT_ACT" 1 "ACTIVE" ;
VAL_ 1822 afe_oc_fltbms 0 "NOT_ACT" 1 "ACTIVE" ;
VAL_ 1822 afe_otf_fltbms 0 "NOT_ACT" 1 "ACTIVE" ;
VAL_ 1822 afe_chgfoff_fltbms 0 "NOT_ACT" 1 "ACTIVE" ;
VAL_ 1822 afe_dsgfoff_fltbms 0 "NOT_ACT" 1 "ACTIVE" ;
VAL_ 1822 ddsg_fltbms 0 "NOT_ACT" 1 "ACTIVE" ;
VAL_ 1822 del_cv_fltbms 0 "NOT_ACT" 1 "ACTIVE" ;
VAL_ 1822 pchg_tout_fltbms 0 "NOT_ACT" 1 "ACTIVE" ;
VAL_ 1822 del_ct_fltbms 0 "NOT_ACT" 1 "ACTIVE" ;
VAL_ 1822 hostl_i2c_fltbms 0 "NOT_ACT" 1 "ACTIVE" ;
VAL_ 1822 hostu_i2c_fltbms 0 "NOT_ACT" 1 "ACTIVE" ;
VAL_ 1822 cot_chg_fltbms 0 "NOT_ACT" 1 "ACTIVE" ;
VAL_ 1822 cot_dsg_fltbms 0 "NOT_ACT" 1 "ACTIVE" ;
VAL_ 1822 cut_chg_fltbms 0 "NOT_ACT" 1 "ACTIVE" ;
VAL_ 1822 cut_dsg_fltbms 0 "NOT_ACT" 1 "ACTIVE" ;
VAL_ 1822 fot_fltbms 0 "NOT_ACT" 1 "ACTIVE" ;
VAL_ 1822 csot_fltbms 0 "NOT_ACT" 1 "ACTIVE" ;
VAL_ 1822 afedieot_fltbms 0 "NOT_ACT" 1 "ACTIVE" ;
VAL_ 1822 imd_fltbms 0 "NOT_ACT" 1 "ACTIVE" ;
VAL_ 1822 hostl_fail_fltbms 0 "NOT_ACT" 1 "ACTIVE" ;
VAL_ 1822 hostu_fail_fltbms 0 "NOT_ACT" 1 "ACTIVE" ;
VAL_ 1822 ctow_fail_fltbms 0 "NOT_ACT" 1 "ACTIVE" ;
VAL_ 1822 nctow_fail_fltbms 0 "NOT_ACT" 1 "ACTIVE" ;
VAL_ 1822 cs_ic_fail_fltbms 0 "NOT_ACT" 1 "ACTIVE" ;
VAL_ 1822 imd_ic_fail_fltbms 0 "NOT_ACT" 1 "ACTIVE" ;
VAL_ 1822 ftow_fail_fltbms 0 "NOT_ACT" 1 "ACTIVE" ;
VAL_ 1822 cstow_fail_fltbms 0 "NOT_ACT" 1 "ACTIVE" ;
VAL_ 1822 aps_scd_fltbms 0 "NOT_ACT" 1 "ACTIVE" ;
VAL_ 1822 aps_ot_fltbms 0 "NOT_ACT" 1 "ACTIVE" ;
VAL_ 1822 aps_ov_fltbms 0 "NOT_ACT" 1 "ACTIVE" ;
VAL_ 1822 aps_oc_fltbms 0 "NOT_ACT" 1 "ACTIVE" ;
VAL_ 1822 fetchg_short_fltbms 0 "NOT_ACT" 1 "ACTIVE" ;
VAL_ 1822 fetdsg_short_fltbms 0 "NOT_ACT" 1 "ACTIVE" ;
VAL_ 1822 pchg_pk_fltbms 0 "NOT_ACT" 1 "ACTIVE" ;
VAL_ 1822 crit_rel_fltbms 0 "NOT_ACT" 1 "ACTIVE" ;
VAL_ 1822 pchg_rot_fltbms 0 "NOT_ACT" 1 "ACTIVE" ;
VAL_ 1822 pchg_rtow_fltbms 0 "NOT_ACT" 1 "ACTIVE" ;
VAL_ 1822 chg_hb_fltbms 0 "NOT_ACT" 1 "ACTIVE" ;
VAL_ 1822 hvil_fltbms 0 "NOT_ACT" 1 "ACTIVE" ;
VAL_ 1822 dsgoff_rel_fltbms 0 "NOT_ACT" 1 "ACTIVE" ;
VAL_ 1822 hazard_fltbms 0 "NOT_ACT" 1 "ACTIVE" ;
VAL_ 1822 hw_scd_fltbms 0 "NOT_ACT" 1 "ACTIVE" ;
VAL_ 1822 sysfail_fltbms 0 "NOT_ACT" 1 "ACTIVE" ;
VAL_ 1822 other_i2c_fail_fltbms 0 "NOT_ACT" 1 "ACTIVE" ;
VAL_ 1822 aps_oc_lat_fltbms 0 "NOT_ACT" 1 "ACTIVE" ;
VAL_ 1822 aps_oc_permlat_fltbms 0 "NOT_ACT" 1 "ACTIVE" ;
VAL_ 1822 ext_opdis_fltbms 0 "NOT_ACT" 1 "ACTIVE" ;
VAL_ 1822 false_chgr_fltbms 0 "NOT_ACT" 1 "ACTIVE" ;
VAL_ 1822 occ1_fltbms 0 "NOT_ACT" 1 "ACTIVE" ;
VAL_ 1822 occ2_fltbms 0 "NOT_ACT" 1 "ACTIVE" ;
VAL_ 1822 occ3_fltbms 0 "NOT_ACT" 1 "ACTIVE" ;
VAL_ 778 BMS_iecu_no 3 "BMS" ;
